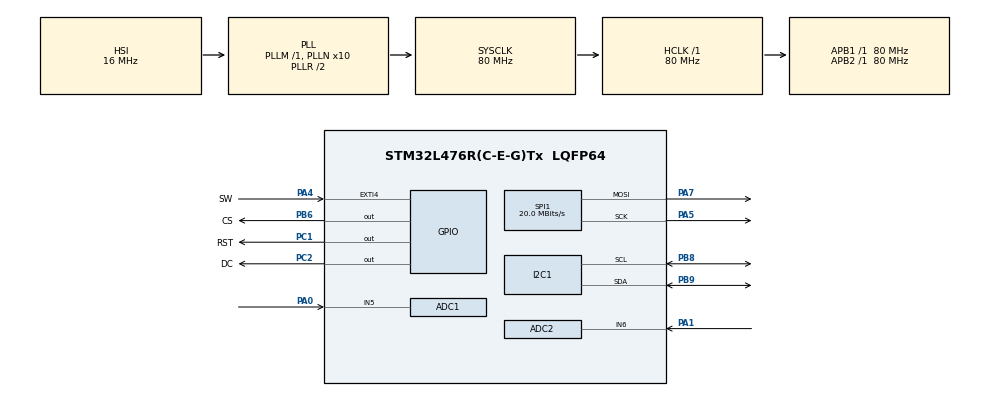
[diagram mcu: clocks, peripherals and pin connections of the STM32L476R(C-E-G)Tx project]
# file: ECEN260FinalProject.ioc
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ADC1.Channel-0\#ChannelRegularConversion=ADC_CHANNEL_5
ADC1.NbrOfConversionFlag=1
ADC1.OffsetNumber-0\#ChannelRegularConversion=ADC_OFFSET_NONE
ADC1.Rank-0\#ChannelRegularConversion=1
ADC1.SamplingTime-0\#ChannelRegularConversion=ADC_SAMPLETIME_2CYCLES_5
ADC1.master=1
ADC2.Channel-0\#ChannelRegularConversion=ADC_CHANNEL_6
ADC2.NbrOfConversionFlag=1
ADC2.OffsetNumber-0\#ChannelRegularConversion=ADC_OFFSET_NONE
ADC2.Rank-0\#ChannelRegularConversion=1
ADC2.SamplingTime-0\#ChannelRegularConversion=ADC_SAMPLETIME_2CYCLES_5
I2C1.Timing=0x10D19CE4
Mcu.Family=STM32L4
Mcu.Name=STM32L476R(C-E-G)Tx
Mcu.Package=LQFP64
NVIC.EXTI4_IRQn=true\:3\:0\:true\:false\:true\:true\:true\:true
NVIC.PriorityGroup=NVIC_PRIORITYGROUP_4
NVIC.TIM1_UP_TIM16_IRQn=true\:1\:0\:true\:false\:true\:true\:true\:true
PA0.Signal=ADCx_IN5
PA1.Signal=ADCx_IN6
PA13\ (JTMS-SWDIO).GPIO_Label=TMS
PA13\ (JTMS-SWDIO).Mode=Serial_Wire
PA13\ (JTMS-SWDIO).Signal=SYS_JTMS-SWDIO
PA14\ (JTCK-SWCLK).GPIO_Label=TCK
PA14\ (JTCK-SWCLK).Mode=Serial_Wire
PA14\ (JTCK-SWCLK).Signal=SYS_JTCK-SWCLK
PA4.GPIO_Label=SW
PA4.GPIO_PuPd=GPIO_PULLUP
PA4.Signal=GPXTI4
PA5.Mode=TX_Only_Simplex_Unidirect_Master
PA5.Signal=SPI1_SCK
PA7.Mode=TX_Only_Simplex_Unidirect_Master
PA7.Signal=SPI1_MOSI
PB3\ (JTDO-TRACESWO).GPIO_Label=SWO
PB3\ (JTDO-TRACESWO).Signal=SYS_JTDO-SWO
PB6.GPIO_Label=CS
PB6.Signal=GPIO_Output
PB8.GPIO_Pu=GPIO_PULLUP
PB8.Mode=I2C
PB8.Signal=I2C1_SCL
PB9.GPIO_Pu=GPIO_PULLUP
PB9.Mode=I2C
PB9.Signal=I2C1_SDA
PC1.GPIO_Label=RST
PC1.Signal=GPIO_Output
PC14-OSC32_IN\ (PC14).Mode=LSE-External-Oscillator
PC14-OSC32_IN\ (PC14).Signal=RCC_OSC32_IN
PC15-OSC32_OUT\ (PC15).Mode=LSE-External-Oscillator
PC15-OSC32_OUT\ (PC15).Signal=RCC_OSC32_OUT
PC2.GPIO_Label=DC
PC2.Signal=GPIO_Output
PH0-OSC_IN\ (PH0).Signal=RCC_OSC_IN
PH1-OSC_OUT\ (PH1).Signal=RCC_OSC_OUT
ProjectManager.HeapSize=0x200
ProjectManager.StackSize=0x400
ProjectManager.TargetToolchain=STM32CubeIDE
RCC.ADCFreq_Value=64000000
RCC.AHBFreq_Value=80000000
RCC.APB1Freq_Value=80000000
RCC.APB1TimFreq_Value=80000000
RCC.APB2Freq_Value=80000000
RCC.APB2TimFreq_Value=80000000
RCC.CortexFreq_Value=80000000
RCC.HCLKFreq_Value=80000000
RCC.HSE_VALUE=8000000
RCC.HSI_VALUE=16000000
RCC.MSI_VALUE=4000000
RCC.PLLN=10
RCC.PLLSourceVirtual=RCC_PLLSOURCE_HSI
RCC.PREFETCH_ENABLE=1
RCC.SYSCLKFreq_VALUE=80000000
RCC.SYSCLKSource=RCC_SYSCLKSOURCE_PLLCLK
RCC.USBFreq_Value=64000000
RCC.VCOOutputFreq_Value=160000000
SH.ADCx_IN5.0=ADC1_IN5,IN5-Single-Ended
SH.ADCx_IN6.0=ADC2_IN6,IN6-Single-Ended
SPI1.BaudRatePrescaler=SPI_BAUDRATEPRESCALER_4
SPI1.CalculateBaudRate=20.0 MBits/s
SPI1.DataSize=SPI_DATASIZE_8BIT
SPI1.Direction=SPI_DIRECTION_2LINES
SPI1.Mode=SPI_MODE_MASTER
SPI1.VirtualType=VM_MASTER
TIM16.Period=999
TIM16.Prescaler=7999
VP_TIM16_VS_ClockSourceINT.Mode=Enable_Timer
board=NUCLEO-L476RG

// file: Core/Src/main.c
/* USER CODE BEGIN Header */
/**
  ******************************************************************************
  * @file           : main.c
  * @brief          : Main program body
  ******************************************************************************
  * @attention
  *
  * Copyright (c) 2025 STMicroelectronics.
  * All rights reserved.
  *
  * This software is licensed under terms that can be found in the LICENSE file
  * in the root directory of this software component.
  * If no LICENSE file comes with this software, it is provided AS-IS.
  *
  ******************************************************************************
  *  Joystick:
  *GND - gnd
  *5V - 3.3V
  *VRx - PA0
  *VRy - PA1
  *SW - PA4
  *  I2C LCD
  *SCL - PB8
  *SDA - PB9
  *VCC - 5V
  *GND - gnd
  *  SPI LCD
  *GND - gnd
  *VDD - 3.3V
  *SCL - PA5
  *SDA - PA7
  *RST - PC1
  *DC - PC2
  *CS - PB6
  *BLK - 3.3V
  */
/* USER CODE END Header */
#include "main.h"

/* USER CODE BEGIN PM */
// 1602 I2C address
#define I2C_ADDR 0x27 // I2C address of the PCF8574
// 1602 dimensions
#define LCD_ROWS 2 // Number of rows on the LCD
#define LCD_COLS 16 // Number of columns on the LCD
// 1602 message bit numbers
#define DC_BIT 0 // Data/Command bit (register select bit)
#define EN_BIT 2 // Enable bit
#define BL_BIT 3 // Backlight bit
#define D4_BIT 4 // Data 4 bit
#define D5_BIT 5 // Data 5 bit
#define D6_BIT 6 // Data 6 bit
#define D7_BIT 7 // Data 7 bit
// Display dimensions
#define NUMROWS 160
#define NUMCOLS 128
// Common 16-bit RGB colors: bbbbb gggggg rrrrr
#define BLACK 0x0000 // 00000 000000 00000
#define WHITE 0xFFFF // 11111 111111 11111
#define BLUE 0xFD14  // 11111 101000 10100
// ST7735 command codes
#define SWRESET 0x01
#define SLPOUT 0x11
#define COLMOD 0x3A
#define MADCTL 0x36
#define DISPON 0x29
#define CASET 0x2A
#define RASET 0x2B
#define RAMWR 0x2C
#define COLOR_MODE_16BIT 0x05
#define MADCTL_DEFAULT 0xC8
/* USER CODE END PM */

ADC_HandleTypeDef hadc1;
ADC_HandleTypeDef hadc2;

I2C_HandleTypeDef hi2c1;

SPI_HandleTypeDef hspi1;

TIM_HandleTypeDef htim16;

/* USER CODE BEGIN PV */
// the background for the display
uint16_t background[160][128] = {
{0,0,0,0,0,0,0,0,0,0,0,0,0,0,0,0,0,0,0,0,0,0,0,0,0,0,0,0,0,0,0,0,0,0,0,0,0,0,0,0,0,0,1,0,0,0,0,0,0,0,0,0,0,0,0,0,0,0,0,0,0,0,0,0,0,0,0,0,0,0,0,0,0,0,0,0,0,0,0,0,0,0,0,0,1,0,0,0,0,0,0,0,0,0,0,0,0,0,0,0,0,0,0,0,0,0,0,0,0,0,0,0,0,0,0,0,0,0,0,0,0,0,0,0,0,0,0,0},
{0,0,0,0,0,0,0,0,0,0,0,0,0,0,0,0,0,0,0,0,0,0,0,0,0,0,0,0,0,0,0,0,0,0,0,0,0,0,0,0,0,0,1,0,0,0,0,0,0,0,0,0,0,0,0,0,0,0,0,0,0,0,0,0,0,0,0,0,0,0,0,0,0,0,0,0,0,0,0,0,0,0,0,0,1,0,0,0,0,0,0,0,0,0,0,0,0,0,0,0,0,0,0,0,0,0,0,0,0,0,0,0,0,0,0,0,0,0,0,0,0,0,0,0,0,0,0,0},
{0,0,0,0,0,0,0,0,0,0,0,0,0,0,0,0,0,0,0,0,0,0,0,0,0,0,0,0,0,0,0,0,0,0,0,0,0,0,0,0,0,0,1,0,0,0,0,0,0,0,0,0,0,0,0,0,0,0,0,0,0,0,0,0,0,0,0,0,0,0,0,0,0,0,0,0,0,0,0,0,0,0,0,0,1,0,0,0,0,0,0,0,0,0,0,0,0,0,0,0,0,0,0,0,0,0,0,0,0,0,0,0,0,0,0,0,0,0,0,0,0,0,0,0,0,0,0,0},
{0,0,0,0,0,0,0,0,0,0,0,0,0,0,0,0,0,0,0,0,0,0,0,0,0,0,0,0,0,0,0,0,0,0,0,0,0,0,0,0,0,0,1,0,0,0,0,0,0,0,0,0,0,0,0,0,0,0,0,0,0,0,0,0,0,0,0,0,0,0,0,0,0,0,0,0,0,0,0,0,0,0,0,0,1,0,0,0,0,0,0,0,0,0,0,0,0,0,0,0,0,0,0,0,0,0,0,0,0,0,0,0,0,0,0,0,0,0,0,0,0,0,0,0,0,0,0,0},
{0,0,0,0,0,0,0,0,0,0,0,0,0,0,0,0,0,0,0,0,0,0,0,0,0,0,0,0,0,0,0,0,0,0,0,0,0,0,0,0,0,0,1,0,0,0,0,0,0,0,0,0,0,0,0,0,0,0,0,0,0,0,0,0,0,0,0,0,0,0,0,0,0,0,0,0,0,0,0,0,0,0,0,0,1,0,0,0,0,0,0,0,0,0,0,0,0,0,0,0,0,0,0,0,0,0,0,0,0,0,0,0,0,0,0,0,0,0,0,0,0,0,0,0,0,0,0,0},
{0,0,0,0,0,0,0,0,0,0,0,0,0,0,0,0,0,0,0,0,0,0,0,0,0,0,0,0,0,0,0,0,0,0,0,0,0,0,0,0,0,0,1,0,0,0,0,0,0,0,0,0,0,0,0,0,0,0,0,0,0,0,0,0,0,0,0,0,0,0,0,0,0,0,0,0,0,0,0,0,0,0,0,0,1,0,0,0,0,0,0,0,0,0,0,0,0,0,0,0,0,0,0,0,0,0,0,0,0,0,0,0,0,0,0,0,0,0,0,0,0,0,0,0,0,0,0,0},
{0,0,0,0,0,0,0,0,0,0,0,0,0,0,0,0,0,0,0,0,0,0,0,0,0,0,0,0,0,0,0,0,0,0,0,0,0,0,0,0,0,0,1,0,0,0,0,0,0,0,0,0,0,0,0,0,0,0,0,0,0,0,0,0,0,0,0,0,0,0,0,0,0,0,0,0,0,0,0,0,0,0,0,0,1,0,0,0,0,0,0,0,0,0,0,0,0,0,0,0,0,0,0,0,0,0,0,0,0,0,0,0,0,0,0,0,0,0,0,0,0,0,0,0,0,0,0,0},
{0,0,0,0,0,0,0,0,0,0,0,0,0,0,0,0,0,0,0,0,0,0,0,0,0,0,0,0,0,0,0,0,0,0,0,0,0,0,0,0,0,0,1,0,0,0,0,0,0,0,0,0,0,0,0,0,0,0,0,0,0,0,0,0,0,0,0,0,0,0,0,0,0,0,0,0,0,0,0,0,0,0,0,0,1,0,0,0,0,0,0,0,0,0,0,0,0,0,0,0,0,0,0,0,0,0,0,0,0,0,0,0,0,0,0,0,0,0,0,0,0,0,0,0,0,0,0,0},
{0,0,0,0,0,0,0,0,0,0,0,0,0,0,0,0,0,0,0,0,0,0,0,0,0,0,0,0,0,0,0,0,0,0,0,0,0,0,0,0,0,0,1,0,0,0,0,0,0,0,0,0,0,0,0,0,0,0,0,0,0,0,0,0,0,0,0,0,0,0,0,0,0,0,0,0,0,0,0,0,0,0,0,0,1,0,0,0,0,0,0,0,0,0,0,0,0,0,0,0,0,0,0,0,0,0,0,0,0,0,0,0,0,0,0,0,0,0,0,0,0,0,0,0,0,0,0,0},
{0,0,0,0,0,0,0,0,0,0,0,0,0,0,0,0,0,0,0,0,0,0,0,0,0,0,0,0,0,0,0,0,0,0,0,0,0,0,0,0,0,0,1,0,0,0,0,0,0,0,0,0,0,0,0,0,0,0,0,0,0,0,0,0,0,0,0,0,0,0,0,0,0,0,0,0,0,0,0,0,0,0,0,0,1,0,0,0,0,0,0,0,0,0,0,0,0,0,0,0,0,0,0,0,0,0,0,0,0,0,0,0,0,0,0,0,0,0,0,0,0,0,0,0,0,0,0,0},
{0,0,0,0,0,0,0,0,0,0,1,1,1,1,1,1,1,1,1,1,1,1,1,1,1,1,1,1,1,1,1,1,0,0,0,0,0,0,0,0,0,0,1,0,0,0,0,0,0,0,0,0,0,0,0,0,0,0,0,0,0,1,1,1,1,1,0,0,0,0,0,0,0,0,0,0,0,0,0,0,0,0,0,0,1,0,0,0,0,0,0,0,0,0,0,0,0,0,0,0,0,1,1,1,1,1,1,1,1,0,0,0,0,0,0,0,0,0,0,0,0,0,0,0,0,0,0,0},
{0,0,0,0,0,0,0,0,0,0,0,0,0,0,0,0,0,0,0,0,0,0,0,0,0,0,0,0,0,0,0,1,0,0,0,0,0,0,0,0,0,0,1,0,0,0,0,0,0,0,0,0,0,0,0,0,0,0,1,1,1,0,0,0,0,0,1,1,1,0,0,0,0,0,0,0,0,0,0,0,0,0,0,0,1,0,0,0,0,0,0,0,0,0,0,0,0,0,0,1,1,0,0,0,0,0,0,0,0,1,1,0,0,0,0,0,0,0,0,0,0,0,0,0,0,0,0,0},
{0,0,0,0,0,0,0,0,0,0,0,0,0,0,0,0,0,0,0,0,0,0,0,0,0,0,0,0,0,0,0,1,0,0,0,0,0,0,0,0,0,0,1,0,0,0,0,0,0,0,0,0,0,0,0,0,1,1,0,0,0,0,0,0,0,0,0,0,0,1,1,0,0,0,0,0,0,0,0,0,0,0,0,0,1,0,0,0,0,0,0,0,0,0,0,0,0,1,1,0,0,0,0,0,0,0,0,0,0,0,0,1,1,0,0,0,0,0,0,0,0,0,0,0,0,0,0,0},
{0,0,0,0,0,0,0,0,0,0,0,0,0,0,0,0,0,0,0,0,0,0,0,0,0,0,0,0,0,0,1,0,0,0,0,0,0,0,0,0,0,0,1,0,0,0,0,0,0,0,0,0,0,0,0,1,0,0,0,0,0,0,0,0,0,0,0,0,0,0,0,1,0,0,0,0,0,0,0,0,0,0,0,0,1,0,0,0,0,0,0,0,0,0,0,0,1,0,0,0,0,0,0,0,0,0,0,0,0,0,0,0,0,1,0,0,0,0,0,0,0,0,0,0,0,0,0,0},
{0,0,0,0,0,0,0,0,0,0,0,0,0,0,0,0,0,0,0,0,0,0,0,0,0,0,0,0,0,0,1,0,0,0,0,0,0,0,0,0,0,0,1,0,0,0,0,0,0,0,0,0,0,0,1,1,0,0,0,0,0,0,0,0,0,0,0,0,0,0,0,0,1,0,0,0,0,0,0,0,0,0,0,0,1,0,0,0,0,0,0,0,0,0,0,0,1,0,0,0,0,0,0,0,0,0,0,0,0,0,0,0,0,1,0,0,0,0,0,0,0,0,0,0,0,0,0,0},
{0,0,0,0,0,0,0,0,0,0,0,0,0,0,0,0,0,0,0,0,0,0,0,0,0,0,0,0,0,1,0,0,0,0,0,0,0,0,0,0,0,0,1,0,0,0,0,0,0,0,0,0,0,1,0,0,0,0,0,0,0,0,0,0,0,0,0,0,0,0,0,0,0,1,0,0,0,0,0,0,0,0,0,0,1,0,0,0,0,0,0,0,0,0,0,1,0,0,0,0,0,0,0,0,0,0,0,0,0,0,0,0,0,0,1,0,0,0,0,0,0,0,0,0,0,0,0,0},
{0,0,0,0,0,0,0,0,0,0,0,0,0,0,0,0,0,0,0,0,0,0,0,0,0,0,0,0,0,1,0,0,0,0,0,0,0,0,0,0,0,0,1,0,0,0,0,0,0,0,0,0,0,1,0,0,0,0,0,0,0,0,0,0,0,0,0,0,0,0,0,0,0,1,0,0,0,0,0,0,0,0,0,0,1,0,0,0,0,0,0,0,0,0,0,1,0,0,0,0,0,0,0,0,0,0,0,0,0,0,0,0,0,0,1,0,0,0,0,0,0,0,0,0,0,0,0,0},
{0,0,0,0,0,0,0,0,0,0,0,0,0,0,0,0,0,0,0,0,0,0,0,0,0,0,0,0,1,0,0,0,0,0,0,0,0,0,0,0,0,0,1,0,0,0,0,0,0,0,0,0,0,1,0,0,0,0,0,0,0,0,0,0,0,0,0,0,0,0,0,0,0,1,0,0,0,0,0,0,0,0,0,0,1,0,0,0,0,0,0,0,0,0,1,0,0,0,0,0,0,0,0,0,0,0,0,0,0,0,0,0,0,0,0,1,0,0,0,0,0,0,0,0,0,0,0,0},
{0,0,0,0,0,0,0,0,0,0,0,0,0,0,0,0,0,0,0,0,0,0,0,0,0,0,0,0,1,0,0,0,0,0,0,0,0,0,0,0,0,0,1,0,0,0,0,0,0,0,0,0,0,1,0,0,0,0,0,0,0,0,0,0,0,0,0,0,0,0,0,0,0,1,0,0,0,0,0,0,0,0,0,0,1,0,0,0,0,0,0,0,0,0,1,0,0,0,0,0,0,0,0,0,0,0,0,0,0,0,0,0,0,0,0,1,0,0,0,0,0,0,0,0,0,0,0,0},
{0,0,0,0,0,0,0,0,0,0,0,0,0,0,0,0,0,0,0,0,0,0,0,0,0,0,0,1,0,0,0,0,0,0,0,0,0,0,0,0,0,0,1,0,0,0,0,0,0,0,0,0,0,1,0,0,0,0,0,0,0,0,0,0,0,0,0,0,0,0,0,0,0,1,0,0,0,0,0,0,0,0,0,0,1,0,0,0,0,0,0,0,0,0,1,0,0,0,0,0,0,0,0,0,0,0,0,0,0,0,0,0,0,0,0,1,0,0,0,0,0,0,0,0,0,0,0,0},
{0,0,0,0,0,0,0,0,0,0,0,0,0,0,0,0,0,0,0,0,0,0,0,0,0,0,0,1,0,0,0,0,0,0,0,0,0,0,0,0,0,0,1,0,0,0,0,0,0,0,0,0,0,0,1,0,0,0,0,0,0,0,0,0,0,0,0,0,0,0,0,0,1,0,0,0,0,0,0,0,0,0,0,0,1,0,0,0,0,0,0,0,0,0,1,0,0,0,0,0,0,0,0,0,0,0,0,0,0,0,0,0,0,0,0,1,0,0,0,0,0,0,0,0,0,0,0,0},
{0,0,0,0,0,0,0,0,0,0,0,0,0,0,0,0,0,0,0,0,0,0,0,0,0,0,1,0,0,0,0,0,0,0,0,0,0,0,0,0,0,0,1,0,0,0,0,0,0,0,0,0,0,0,0,1,0,0,0,0,0,0,0,0,0,0,0,0,0,0,0,1,0,0,0,0,0,0,0,0,0,0,0,0,1,0,0,0,0,0,0,0,0,0,1,0,0,0,0,0,0,0,0,0,0,0,0,0,0,0,0,0,0,0,0,1,0,0,0,0,0,0,0,0,0,0,0,0},
{0,0,0,0,0,0,0,0,0,0,0,0,0,0,0,0,0,0,0,0,0,0,0,0,0,0,1,0,0,0,0,0,0,0,0,0,0,0,0,0,0,0,1,0,0,0,0,0,0,0,0,0,0,0,0,0,1,1,1,0,0,0,0,0,0,0,0,0,1,1,1,0,0,0,0,0,0,0,0,0,0,0,0,0,1,0,0,0,0,0,0,0,0,0,1,0,0,0,0,0,0,0,0,0,0,0,0,0,0,0,0,0,0,0,0,1,0,0,0,0,0,0,0,0,0,0,0,0},
{0,0,0,0,0,0,0,0,0,0,0,0,0,0,0,0,0,0,0,0,0,0,0,0,0,1,0,0,0,0,0,0,0,0,0,0,0,0,0,0,0,0,1,0,0,0,0,0,0,0,0,0,0,0,0,0,0,0,0,1,1,1,0,0,0,1,1,1,0,0,0,0,0,0,0,0,0,0,0,0,0,0,0,0,1,0,0,0,0,0,0,0,0,0,0,1,0,0,0,0,0,0,0,0,0,0,0,0,0,0,0,0,0,0,1,1,0,0,0,0,0,0,0,0,0,0,0,0},
{0,0,0,0,0,0,0,0,0,0,0,0,0,0,0,0,0,0,0,0,0,0,0,0,0,1,0,0,0,0,0,0,0,0,0,0,0,0,0,0,0,0,1,0,0,0,0,0,0,0,0,0,0,0,0,0,0,0,0,0,0,0,1,1,1,0,0,0,0,0,0,0,0,0,0,0,0,0,0,0,0,0,0,0,1,0,0,0,0,0,0,0,0,0,0,1,0,0,0,0,0,0,0,0,0,0,0,0,0,0,0,0,0,0,1,1,0,0,0,0,0,0,0,0,0,0,0,0},
{0,0,0,0,0,0,0,0,0,0,0,0,0,0,0,0,0,0,0,0,0,0,0,0,1,0,0,0,0,0,0,0,0,0,0,0,0,0,0,0,0,0,1,0,0,0,0,0,0,0,0,0,0,0,0,0,0,0,0,1,1,1,0,0,0,1,1,1,0,0,0,0,0,0,0,0,0,0,0,0,0,0,0,0,1,0,0,0,0,0,0,0,0,0,0,0,1,0,0,0,0,0,0,0,0,0,0,0,0,0,0,0,0,1,0,1,0,0,0,0,0,0,0,0,0,0,0,0},
{0,0,0,0,0,0,0,0,0,0,0,0,0,0,0,0,0,0,0,0,0,0,0,0,1,0,0,0,0,0,0,0,0,0,0,0,0,0,0,0,0,0,1,0,0,0,0,0,0,0,0,0,0,0,0,0,0,1,1,0,0,0,0,0,0,0,0,0,1,1,0,0,0,0,0,0,0,0,0,0,0,0,0,0,1,0,0,0,0,0,0,0,0,0,0,0,1,0,0,0,0,0,0,0,0,0,0,0,0,0,0,0,0,1,0,1,0,0,0,0,0,0,0,0,0,0,0,0},
{0,0,0,0,0,0,0,0,0,0,0,0,0,0,0,0,0,0,0,0,0,0,0,1,0,0,0,0,0,0,0,0,0,0,0,0,0,0,0,0,0,0,1,0,0,0,0,0,0,0,0,0,0,0,0,0,1,0,0,0,0,0,0,0,0,0,0,0,0,0,1,0,0,0,0,0,0,0,0,0,0,0,0,0,1,0,0,0,0,0,0,0,0,0,0,0,0,1,1,0,0,0,0,0,0,0,0,0,0,0,0,1,1,0,0,1,0,0,0,0,0,0,0,0,0,0,0,0},
{0,0,0,0,0,0,0,0,0,0,0,0,0,0,0,0,0,0,0,0,0,0,0,1,0,0,0,0,0,0,0,0,0,0,0,0,0,0,0,0,0,0,1,0,0,0,0,0,0,0,0,0,0,0,0,1,0,0,0,0,0,0,0,0,0,0,0,0,0,0,0,1,0,0,0,0,0,0,0,0,0,0,0,0,1,0,0,0,0,0,0,0,0,0,0,0,0,0,0,1,1,0,0,0,0,0,0,0,0,1,1,0,0,0,0,1,0,0,0,0,0,0,0,0,0,0,0,0},
{0,0,0,0,0,0,0,0,0,0,0,0,0,0,0,0,0,0,0,0,0,0,1,0,0,0,0,0,0,0,0,0,0,0,0,0,0,0,0,0,0,0,1,0,0,0,0,0,0,0,0,0,0,0,1,0,0,0,0,0,0,0,0,0,0,0,0,0,0,0,0,0,1,0,0,0,0,0,0,0,0,0,0,0,1,0,0,0,0,0,0,0,0,0,0,0,0,0,0,0,0,1,1,1,1,1,1,1,1,0,0,0,0,0,1,0,0,0,0,0,0,0,0,0,0,0,0,0},
{0,0,0,0,0,0,0,0,0,0,0,0,0,0,0,0,0,0,0,0,0,0,1,0,0,0,0,0,0,0,0,0,0,0,0,0,0,0,0,0,0,0,1,0,0,0,0,0,0,0,0,0,0,1,0,0,0,0,0,0,0,0,0,0,0,0,0,0,0,0,0,0,0,1,0,0,0,0,0,0,0,0,0,0,1,0,0,0,0,0,0,0,0,0,0,0,0,0,0,0,0,0,0,0,0,0,0,0,0,0,0,0,0,0,1,0,0,0,0,0,0,0,0,0,0,0,0,0},
{0,0,0,0,0,0,0,0,0,0,0,0,0,0,0,0,0,0,0,0,0,1,0,0,0,0,0,0,0,0,0,0,0,0,0,0,0,0,0,0,0,0,1,0,0,0,0,0,0,0,0,0,0,1,0,0,0,0,0,0,0,0,0,0,0,0,0,0,0,0,0,0,0,1,0,0,0,0,0,0,0,0,0,0,1,0,0,0,0,0,0,0,0,0,0,0,0,0,0,0,0,0,0,0,0,0,0,0,0,0,0,0,0,0,1,0,0,0,0,0,0,0,0,0,0,0,0,0},
{0,0,0,0,0,0,0,0,0,0,0,0,0,0,0,0,0,0,0,0,0,1,0,0,0,0,0,0,0,0,0,0,0,0,0,0,0,0,0,0,0,0,1,0,0,0,0,0,0,0,0,0,0,1,0,0,0,0,0,0,0,0,0,0,0,0,0,0,0,0,0,0,0,1,0,0,0,0,0,0,0,0,0,0,1,0,0,0,0,0,0,0,0,0,0,0,0,0,0,0,0,0,0,0,0,0,0,0,0,0,0,0,0,1,0,0,0,0,0,0,0,0,0,0,0,0,0,0},
{0,0,0,0,0,0,0,0,0,0,0,0,0,0,0,0,0,0,0,0,1,0,0,0,0,0,0,0,0,0,0,0,0,0,0,0,0,0,0,0,0,0,1,0,0,0,0,0,0,0,0,0,0,1,0,0,0,0,0,0,0,0,0,0,0,0,0,0,0,0,0,0,0,1,0,0,0,0,0,0,0,0,0,0,1,0,0,0,0,0,0,0,0,0,0,0,0,0,0,0,0,0,0,0,0,0,0,0,0,0,0,0,0,1,0,0,0,0,0,0,0,0,0,0,0,0,0,0},
{0,0,0,0,0,0,0,0,0,0,0,0,0,0,0,0,0,0,0,0,1,0,0,0,0,0,0,0,0,0,0,0,0,0,0,0,0,0,0,0,0,0,1,0,0,0,0,0,0,0,0,0,0,1,0,0,0,0,0,0,0,0,0,0,0,0,0,0,0,0,0,0,0,1,0,0,0,0,0,0,0,0,0,0,1,0,0,0,0,0,0,0,0,0,0,0,0,0,0,0,0,0,0,0,0,0,0,0,0,0,0,0,0,1,0,0,0,0,0,0,0,0,0,0,0,0,0,0},
{0,0,0,0,0,0,0,0,0,0,0,0,0,0,0,0,0,0,0,1,0,0,0,0,0,0,0,0,0,0,0,0,0,0,0,0,0,0,0,0,0,0,1,0,0,0,0,0,0,0,0,0,0,0,1,0,0,0,0,0,0,0,0,0,0,0,0,0,0,0,0,0,1,0,0,0,0,0,0,0,0,0,0,0,1,0,0,0,0,0,0,0,0,0,0,0,0,0,0,0,0,0,0,0,0,0,0,0,0,0,0,0,1,0,0,0,0,0,0,0,0,0,0,0,0,0,0,0},
{0,0,0,0,0,0,0,0,0,0,0,0,0,0,0,0,0,0,0,1,0,0,0,0,0,0,0,0,0,0,0,0,0,0,0,0,0,0,0,0,0,0,1,0,0,0,0,0,0,0,0,0,0,0,1,0,0,0,0,0,0,0,0,0,0,0,0,0,0,0,0,0,1,0,0,0,0,0,0,0,0,0,0,0,1,0,0,0,0,0,0,0,0,0,0,0,0,0,0,0,0,0,0,0,0,0,0,0,0,0,0,0,1,0,0,0,0,0,0,0,0,0,0,0,0,0,0,0},
{0,0,0,0,0,0,0,0,0,0,0,0,0,0,0,0,0,0,1,0,0,0,0,0,0,0,0,0,0,0,0,0,0,0,0,0,0,0,0,0,0,0,1,0,0,0,0,0,0,0,0,0,0,0,0,1,0,0,0,0,0,0,0,0,0,0,0,0,0,0,0,1,0,0,0,0,0,0,0,0,0,0,0,0,1,0,0,0,0,0,0,0,0,0,0,0,0,0,0,0,0,0,0,0,0,0,0,0,0,0,0,1,0,0,0,0,0,0,0,0,0,0,0,0,0,0,0,0},
{0,0,0,0,0,0,0,0,0,0,0,0,0,0,0,0,0,0,1,0,0,0,0,0,0,0,0,0,0,0,0,0,0,0,0,0,0,0,0,0,0,0,1,0,0,0,0,0,0,0,0,0,0,0,0,1,0,0,0,0,0,0,0,0,0,0,0,0,0,0,0,1,0,0,0,0,0,0,0,0,0,0,0,0,1,0,0,0,0,0,0,0,0,0,0,0,0,0,0,0,0,0,0,0,0,0,0,0,0,0,0,1,0,0,0,0,0,0,0,0,0,0,0,0,0,0,0,0},
{0,0,0,0,0,0,0,0,0,0,0,0,0,0,0,0,0,1,0,0,0,0,0,0,0,0,0,0,0,0,0,0,0,0,0,0,0,0,0,0,0,0,1,0,0,0,0,0,0,0,0,0,0,0,0,0,1,1,0,0,0,0,0,0,0,0,0,0,0,1,1,0,0,0,0,0,0,0,0,0,0,0,0,0,1,0,0,0,0,0,0,0,0,0,0,0,0,0,0,0,0,0,0,0,0,0,0,0,0,0,1,0,0,0,0,0,0,0,0,0,0,0,0,0,0,0,0,0},
{0,0,0,0,0,0,0,0,0,0,0,0,0,0,0,0,0,1,0,0,0,0,0,0,0,0,0,0,0,0,0,0,0,0,0,0,0,0,0,0,0,0,1,0,0,0,0,0,0,0,0,0,0,0,0,0,0,0,1,1,0,0,0,0,0,0,0,1,1,0,0,0,0,0,0,0,0,0,0,0,0,0,0,0,1,0,0,0,0,0,0,0,0,0,0,0,0,0,0,0,0,0,0,0,0,0,0,0,1,1,0,0,0,0,0,0,0,0,0,0,0,0,0,0,0,0,0,0},
{0,0,0,0,0,0,0,0,0,0,0,0,0,0,0,0,1,0,0,0,0,0,0,0,0,0,0,0,0,0,0,0,0,0,0,0,0,0,0,0,0,0,1,0,0,0,0,0,0,0,0,0,0,0,0,0,0,0,0,0,1,1,1,1,1,1,1,0,0,0,0,0,0,0,0,0,0,0,0,0,0,0,0,0,1,0,0,0,0,0,0,0,0,0,0,0,0,0,0,0,0,1,1,1,1,1,1,1,0,0,0,0,0,0,0,0,0,0,0,0,0,0,0,0,0,0,0,0},
{0,0,0,0,0,0,0,0,0,0,0,0,0,0,0,0,0,0,0,0,0,0,0,0,0,0,0,0,0,0,0,0,0,0,0,0,0,0,0,0,0,0,1,0,0,0,0,0,0,0,0,0,0,0,0,0,0,0,0,0,0,0,0,0,0,0,0,0,0,0,0,0,0,0,0,0,0,0,0,0,0,0,0,0,1,0,0,0,0,0,0,0,0,0,0,0,0,0,0,0,0,0,0,0,0,0,0,0,0,0,0,0,0,0,0,0,0,0,0,0,0,0,0,0,0,0,0,0},
{0,0,0,0,0,0,0,0,0,0,0,0,0,0,0,0,0,0,0,0,0,0,0,0,0,0,0,0,0,0,0,0,0,0,0,0,0,0,0,0,0,0,1,0,0,0,0,0,0,0,0,0,0,0,0,0,0,0,0,0,0,0,0,0,0,0,0,0,0,0,0,0,0,0,0,0,0,0,0,0,0,0,0,0,1,0,0,0,0,0,0,0,0,0,0,0,0,0,0,0,0,0,0,0,0,0,0,0,0,0,0,0,0,0,0,0,0,0,0,0,0,0,0,0,0,0,0,0},
{0,0,0,0,0,0,0,0,0,0,0,0,0,0,0,0,0,0,0,0,0,0,0,0,0,0,0,0,0,0,0,0,0,0,0,0,0,0,0,0,0,0,1,0,0,0,0,0,0,0,0,0,0,0,0,0,0,0,0,0,0,0,0,0,0,0,0,0,0,0,0,0,0,0,0,0,0,0,0,0,0,0,0,0,1,0,0,0,0,0,0,0,0,0,0,0,0,0,0,0,0,0,0,0,0,0,0,0,0,0,0,0,0,0,0,0,0,0,0,0,0,0,0,0,0,0,0,0},
{0,0,0,0,0,0,0,0,0,0,0,0,0,0,0,0,0,0,0,0,0,0,0,0,0,0,0,0,0,0,0,0,0,0,0,0,0,0,0,0,0,0,1,0,0,0,0,0,0,0,0,0,0,0,0,0,0,0,0,0,0,0,0,0,0,0,0,0,0,0,0,0,0,0,0,0,0,0,0,0,0,0,0,0,1,0,0,0,0,0,0,0,0,0,0,0,0,0,0,0,0,0,0,0,0,0,0,0,0,0,0,0,0,0,0,0,0,0,0,0,0,0,0,0,0,0,0,0},
{0,0,0,0,0,0,0,0,0,0,0,0,0,0,0,0,0,0,0,0,0,0,0,0,0,0,0,0,0,0,0,0,0,0,0,0,0,0,0,0,0,0,1,0,0,0,0,0,0,0,0,0,0,0,0,0,0,0,0,0,0,0,0,0,0,0,0,0,0,0,0,0,0,0,0,0,0,0,0,0,0,0,0,0,1,0,0,0,0,0,0,0,0,0,0,0,0,0,0,0,0,0,0,0,0,0,0,0,0,0,0,0,0,0,0,0,0,0,0,0,0,0,0,0,0,0,0,0},
{0,0,0,0,0,0,0,0,0,0,0,0,0,0,0,0,0,0,0,0,0,0,0,0,0,0,0,0,0,0,0,0,0,0,0,0,0,0,0,0,0,0,1,0,0,0,0,0,0,0,0,0,0,0,0,0,0,0,0,0,0,0,0,0,0,0,0,0,0,0,0,0,0,0,0,0,0,0,0,0,0,0,0,0,1,0,0,0,0,0,0,0,0,0,0,0,0,0,0,0,0,0,0,0,0,0,0,0,0,0,0,0,0,0,0,0,0,0,0,0,0,0,0,0,0,0,0,0},
{0,0,0,0,0,0,0,0,0,0,0,0,0,0,0,0,0,0,0,0,0,0,0,0,0,0,0,0,0,0,0,0,0,0,0,0,0,0,0,0,0,0,1,0,0,0,0,0,0,0,0,0,0,0,0,0,0,0,0,0,0,0,0,0,0,0,0,0,0,0,0,0,0,0,0,0,0,0,0,0,0,0,0,0,1,0,0,0,0,0,0,0,0,0,0,0,0,0,0,0,0,0,0,0,0,0,0,0,0,0,0,0,0,0,0,0,0,0,0,0,0,0,0,0,0,0,0,0},
{0,0,0,0,0,0,0,0,0,0,0,0,0,0,0,0,0,0,0,0,0,0,0,0,0,0,0,0,0,0,0,0,0,0,0,0,0,0,0,0,0,0,1,0,0,0,0,0,0,0,0,0,0,0,0,0,0,0,0,0,0,0,0,0,0,0,0,0,0,0,0,0,0,0,0,0,0,0,0,0,0,0,0,0,1,0,0,0,0,0,0,0,0,0,0,0,0,0,0,0,0,0,0,0,0,0,0,0,0,0,0,0,0,0,0,0,0,0,0,0,0,0,0,0,0,0,0,0},
{0,0,0,0,0,0,0,0,0,0,0,0,0,0,0,0,0,0,0,0,0,0,0,0,0,0,0,0,0,0,0,0,0,0,0,0,0,0,0,0,0,0,1,0,0,0,0,0,0,0,0,0,0,0,0,0,0,0,0,0,0,0,0,0,0,0,0,0,0,0,0,0,0,0,0,0,0,0,0,0,0,0,0,0,1,0,0,0,0,0,0,0,0,0,0,0,0,0,0,0,0,0,0,0,0,0,0,0,0,0,0,0,0,0,0,0,0,0,0,0,0,0,0,0,0,0,0,0},
{0,0,0,0,0,0,0,0,0,0,0,0,0,0,0,0,0,0,0,0,0,0,0,0,0,0,0,0,0,0,0,0,0,0,0,0,0,0,0,0,0,0,1,0,0,0,0,0,0,0,0,0,0,0,0,0,0,0,0,0,0,0,0,0,0,0,0,0,0,0,0,0,0,0,0,0,0,0,0,0,0,0,0,0,1,0,0,0,0,0,0,0,0,0,0,0,0,0,0,0,0,0,0,0,0,0,0,0,0,0,0,0,0,0,0,0,0,0,0,0,0,0,0,0,0,0,0,0},
{1,1,1,1,1,1,1,1,1,1,1,1,1,1,1,1,1,1,1,1,1,1,1,1,1,1,1,1,1,1,1,1,1,1,1,1,1,1,1,1,1,1,1,1,1,1,1,1,1,1,1,1,1,1,1,1,1,1,1,1,1,1,1,1,1,1,1,1,1,1,1,1,1,1,1,1,1,1,1,1,1,1,1,1,1,1,1,1,1,1,1,1,1,1,1,1,1,1,1,1,1,1,1,1,1,1,1,1,1,1,1,1,1,1,1,1,1,1,1,1,1,1,1,1,1,1,1,1},
{0,0,0,0,0,0,0,0,0,0,0,0,0,0,0,0,0,0,0,0,0,0,0,0,0,0,0,0,0,0,0,0,0,0,0,0,0,0,0,0,0,0,1,0,0,0,0,0,0,0,0,0,0,0,0,0,0,0,0,0,0,0,0,0,0,0,0,0,0,0,0,0,0,0,0,0,0,0,0,0,0,0,0,0,1,0,0,0,0,0,0,0,0,0,0,0,0,0,0,0,0,0,0,0,0,0,0,0,0,0,0,0,0,0,0,0,0,0,0,0,0,0,0,0,0,0,0,0},
{0,0,0,0,0,0,0,0,0,0,0,0,0,0,0,0,0,0,0,0,0,0,0,0,0,0,0,0,0,0,0,0,0,0,0,0,0,0,0,0,0,0,1,0,0,0,0,0,0,0,0,0,0,0,0,0,0,0,0,0,0,0,0,0,0,0,0,0,0,0,0,0,0,0,0,0,0,0,0,0,0,0,0,0,1,0,0,0,0,0,0,0,0,0,0,0,0,0,0,0,0,0,0,0,0,0,0,0,0,0,0,0,0,0,0,0,0,0,0,0,0,0,0,0,0,0,0,0},
{0,0,0,0,0,0,0,0,0,0,0,0,0,0,0,0,0,0,0,0,0,0,0,0,0,0,0,0,0,0,0,0,0,0,0,0,0,0,0,0,0,0,1,0,0,0,0,0,0,0,0,0,0,0,0,0,0,0,0,0,0,0,0,0,0,0,0,0,0,0,0,0,0,0,0,0,0,0,0,0,0,0,0,0,1,0,0,0,0,0,0,0,0,0,0,0,0,0,0,0,0,0,0,0,0,0,0,0,0,0,0,0,0,0,0,0,0,0,0,0,0,0,0,0,0,0,0,0},
{0,0,0,0,0,0,0,0,0,0,0,0,0,0,0,0,0,0,0,0,0,0,0,0,0,0,0,0,0,0,0,0,0,0,0,0,0,0,0,0,0,0,1,0,0,0,0,0,0,0,0,0,0,0,0,0,0,0,0,0,0,0,0,0,0,0,0,0,0,0,0,0,0,0,0,0,0,0,0,0,0,0,0,0,1,0,0,0,0,0,0,0,0,0,0,0,0,0,0,0,0,0,0,0,0,0,0,0,0,0,0,0,0,0,0,0,0,0,0,0,0,0,0,0,0,0,0,0},
{0,0,0,0,0,0,0,0,0,0,0,0,0,0,0,0,0,0,0,0,0,0,0,0,0,0,0,0,0,0,0,0,0,0,0,0,0,0,0,0,0,0,1,0,0,0,0,0,0,0,0,0,0,0,0,0,0,0,0,0,0,0,0,0,0,0,0,0,0,0,0,0,0,0,0,0,0,0,0,0,0,0,0,0,1,0,0,0,0,0,0,0,0,0,0,0,0,0,0,0,0,0,0,0,0,0,0,0,0,0,0,0,0,0,0,0,0,0,0,0,0,0,0,0,0,0,0,0},
{0,0,0,0,0,0,0,0,0,0,0,0,0,0,0,0,0,0,0,0,0,0,0,0,0,0,0,0,0,0,0,0,0,0,0,0,0,0,0,0,0,0,1,0,0,0,0,0,0,0,0,0,0,0,0,0,0,0,0,0,0,0,0,0,0,0,0,0,0,0,0,0,0,0,0,0,0,0,0,0,0,0,0,0,1,0,0,0,0,0,0,0,0,0,0,0,0,0,0,0,0,0,0,0,0,0,0,0,0,0,0,0,0,0,0,0,0,0,0,0,0,0,0,0,0,0,0,0},
{0,0,0,0,0,0,0,0,0,0,0,0,0,0,0,0,0,0,0,0,0,0,0,0,0,0,0,0,0,0,0,0,0,0,0,0,0,0,0,0,0,0,1,0,0,0,0,0,0,0,0,0,0,0,0,0,0,0,0,0,0,0,0,0,0,0,0,0,0,0,0,0,0,0,0,0,0,0,0,0,0,0,0,0,1,0,0,0,0,0,0,0,0,0,0,0,0,0,0,0,0,0,0,0,0,0,0,0,0,0,0,0,0,0,0,0,0,0,0,0,0,0,0,0,0,0,0,0},
{0,0,0,0,0,0,0,0,0,0,0,0,0,0,0,0,0,0,0,0,0,0,0,0,0,0,0,0,0,0,0,0,0,0,0,0,0,0,0,0,0,0,1,0,0,0,0,0,0,0,0,0,0,0,0,0,0,0,0,0,0,0,0,0,0,0,0,0,0,0,0,0,0,0,0,0,0,0,0,0,0,0,0,0,1,0,0,0,0,0,0,0,0,0,0,0,0,0,0,0,0,0,0,0,0,0,0,0,0,0,0,0,0,0,0,0,0,0,0,0,0,0,0,0,0,0,0,0},
{0,0,0,0,0,0,0,0,0,0,0,0,0,0,0,0,0,0,0,0,0,0,0,1,0,0,0,0,0,0,0,0,0,0,0,0,0,0,0,0,0,0,1,0,0,0,0,0,0,0,0,0,0,0,0,0,0,0,0,0,0,0,0,0,0,0,0,0,0,0,0,0,0,0,0,0,0,0,0,0,0,0,0,0,1,0,0,0,0,0,0,0,0,0,0,0,0,0,0,0,0,0,0,0,0,0,0,0,0,0,0,0,0,0,0,0,0,0,0,0,0,0,0,0,0,0,0,0},
{0,0,0,0,0,0,0,0,0,0,0,0,0,0,0,0,0,0,0,0,0,0,1,1,0,0,0,0,0,0,0,0,0,0,0,0,0,0,0,0,0,0,1,0,0,0,0,0,0,0,0,0,0,0,0,0,0,0,0,0,0,0,0,0,0,0,0,0,0,0,0,0,0,0,0,0,0,0,0,0,0,0,0,0,1,0,0,0,0,0,0,0,0,0,0,0,0,0,0,0,0,0,0,0,0,0,0,0,0,0,0,0,0,0,0,0,0,0,0,0,0,0,0,0,0,0,0,0},
{0,0,0,0,0,0,0,0,0,0,0,0,0,0,0,0,0,0,0,0,0,1,0,1,0,0,0,0,0,0,0,0,0,0,0,0,0,0,0,0,0,0,1,0,0,0,0,0,0,0,0,0,0,1,1,1,1,1,1,1,1,1,1,1,1,1,1,1,1,1,1,1,1,1,0,0,0,0,0,0,0,0,0,0,1,0,0,0,0,0,0,0,0,0,0,0,0,0,0,0,0,0,0,0,0,0,1,1,1,1,0,0,0,0,0,0,0,0,0,0,0,0,0,0,0,0,0,0},
{0,0,0,0,0,0,0,0,0,0,0,0,0,0,0,0,0,0,0,0,1,0,0,1,0,0,0,0,0,0,0,0,0,0,0,0,0,0,0,0,0,0,1,0,0,0,0,0,0,0,0,0,0,1,0,0,0,0,0,0,0,0,0,0,0,0,0,0,0,0,0,0,0,0,0,0,0,0,0,0,0,0,0,0,1,0,0,0,0,0,0,0,0,0,0,0,0,0,0,0,0,0,0,1,1,1,0,0,0,0,0,0,0,0,0,0,0,0,0,0,0,0,0,0,0,0,0,0},
{0,0,0,0,0,0,0,0,0,0,0,0,0,0,0,0,0,0,0,1,0,0,0,1,0,0,0,0,0,0,0,0,0,0,0,0,0,0,0,0,0,0,1,0,0,0,0,0,0,0,0,0,0,1,0,0,0,0,0,0,0,0,0,0,0,0,0,0,0,0,0,0,0,0,0,0,0,0,0,0,0,0,0,0,1,0,0,0,0,0,0,0,0,0,0,0,0,0,0,0,0,1,1,0,0,0,0,0,0,0,0,0,0,0,0,0,0,0,0,0,0,0,0,0,0,0,0,0},
{0,0,0,0,0,0,0,0,0,0,0,0,0,0,0,0,0,0,1,0,0,0,0,1,0,0,0,0,0,0,0,0,0,0,0,0,0,0,0,0,0,0,1,0,0,0,0,0,0,0,0,0,0,1,0,0,0,0,0,0,0,0,0,0,0,0,0,0,0,0,0,0,0,0,0,0,0,0,0,0,0,0,0,0,1,0,0,0,0,0,0,0,0,0,0,0,0,0,0,0,1,0,0,0,0,0,0,0,0,0,0,0,0,0,0,0,0,0,0,0,0,0,0,0,0,0,0,0},
{0,0,0,0,0,0,0,0,0,0,0,0,0,0,0,0,0,1,0,0,0,0,0,1,0,0,0,0,0,0,0,0,0,0,0,0,0,0,0,0,0,0,1,0,0,0,0,0,0,0,0,0,0,1,0,0,0,0,0,0,0,0,0,0,0,0,0,0,0,0,0,0,0,0,0,0,0,0,0,0,0,0,0,0,1,0,0,0,0,0,0,0,0,0,0,0,0,0,0,1,0,0,0,0,0,0,0,0,0,0,0,0,0,0,0,0,0,0,0,0,0,0,0,0,0,0,0,0},
{0,0,0,0,0,0,0,0,0,0,0,0,0,0,0,0,1,0,0,0,0,0,0,1,0,0,0,0,0,0,0,0,0,0,0,0,0,0,0,0,0,0,1,0,0,0,0,0,0,0,0,0,0,1,0,0,0,0,0,0,0,0,0,0,0,0,0,0,0,0,0,0,0,0,0,0,0,0,0,0,0,0,0,0,1,0,0,0,0,0,0,0,0,0,0,0,0,0,1,0,0,0,0,0,0,0,0,0,0,0,0,0,0,0,0,0,0,0,0,0,0,0,0,0,0,0,0,0},
{0,0,0,0,0,0,0,0,0,0,0,0,0,0,0,1,0,0,0,0,0,0,0,1,0,0,0,0,0,0,0,0,0,0,0,0,0,0,0,0,0,0,1,0,0,0,0,0,0,0,0,0,0,1,0,0,0,0,0,0,0,0,0,0,0,0,0,0,0,0,0,0,0,0,0,0,0,0,0,0,0,0,0,0,1,0,0,0,0,0,0,0,0,0,0,0,0,0,1,0,0,0,0,0,0,0,0,0,0,0,0,0,0,0,0,0,0,0,0,0,0,0,0,0,0,0,0,0},
{0,0,0,0,0,0,0,0,0,0,0,0,0,0,1,0,0,0,0,0,0,0,0,1,0,0,0,0,0,0,0,0,0,0,0,0,0,0,0,0,0,0,1,0,0,0,0,0,0,0,0,0,0,1,0,0,0,0,0,0,0,0,0,0,0,0,0,0,0,0,0,0,0,0,0,0,0,0,0,0,0,0,0,0,1,0,0,0,0,0,0,0,0,0,0,0,0,1,0,0,0,0,0,0,0,0,0,0,0,0,0,0,0,0,0,0,0,0,0,0,0,0,0,0,0,0,0,0},
{0,0,0,0,0,0,0,0,0,0,0,0,0,1,0,0,0,0,0,0,0,0,0,1,0,0,0,0,0,0,0,0,0,0,0,0,0,0,0,0,0,0,1,0,0,0,0,0,0,0,0,0,0,1,0,0,0,0,0,0,0,0,0,0,0,0,0,0,0,0,0,0,0,0,0,0,0,0,0,0,0,0,0,0,1,0,0,0,0,0,0,0,0,0,0,0,0,1,0,0,0,0,0,0,0,0,0,0,0,0,0,0,0,0,0,0,0,0,0,0,0,0,0,0,0,0,0,0},
{0,0,0,0,0,0,0,0,0,0,0,0,1,0,0,0,0,0,0,0,0,0,0,1,0,0,0,0,0,0,0,0,0,0,0,0,0,0,0,0,0,0,1,0,0,0,0,0,0,0,0,0,0,1,0,0,0,0,0,0,0,0,0,0,0,0,0,0,0,0,0,0,0,0,0,0,0,0,0,0,0,0,0,0,1,0,0,0,0,0,0,0,0,0,0,0,0,1,0,0,0,0,0,0,0,0,0,0,0,0,0,0,0,0,0,0,0,0,0,0,0,0,0,0,0,0,0,0},
{0,0,0,0,0,0,0,0,0,0,0,1,0,0,0,0,0,0,0,0,0,0,0,1,0,0,0,0,0,0,0,0,0,0,0,0,0,0,0,0,0,0,1,0,0,0,0,0,0,0,0,0,0,1,0,0,0,0,0,0,0,0,0,0,0,0,0,0,0,0,0,0,0,0,0,0,0,0,0,0,0,0,0,0,1,0,0,0,0,0,0,0,0,0,0,0,1,0,0,0,0,0,0,0,0,0,0,0,0,0,0,0,0,0,0,0,0,0,0,0,0,0,0,0,0,0,0,0},
{0,0,0,0,0,0,0,0,0,0,1,0,0,0,0,0,0,0,0,0,0,0,0,1,0,0,0,0,0,0,0,0,0,0,0,0,0,0,0,0,0,0,1,0,0,0,0,0,0,0,0,0,0,1,0,0,0,0,0,0,0,0,0,0,0,0,0,0,0,0,0,0,0,0,0,0,0,0,0,0,0,0,0,0,1,0,0,0,0,0,0,0,0,0,0,0,1,0,0,0,0,0,0,0,0,0,0,0,0,0,0,0,0,0,0,0,0,0,0,0,0,0,0,0,0,0,0,0},
{0,0,0,0,0,0,0,0,0,1,0,0,0,0,0,0,0,0,0,0,0,0,0,1,0,0,0,0,0,0,0,0,0,0,0,0,0,0,0,0,0,0,1,0,0,0,0,0,0,0,0,0,0,1,0,0,0,0,0,0,0,0,0,0,0,0,0,0,0,0,0,0,0,0,0,0,0,0,0,0,0,0,0,0,1,0,0,0,0,0,0,0,0,0,0,0,1,0,0,0,0,0,0,0,0,0,0,0,0,0,0,0,0,0,0,0,0,0,0,0,0,0,0,0,0,0,0,0},
{0,0,0,0,0,0,0,0,1,1,1,1,1,1,1,1,1,1,1,1,1,1,1,1,1,1,1,1,1,1,1,0,0,0,0,0,0,0,0,0,0,0,1,0,0,0,0,0,0,0,0,0,0,1,0,0,0,0,0,0,1,1,1,1,1,1,1,0,0,0,0,0,0,0,0,0,0,0,0,0,0,0,0,0,1,0,0,0,0,0,0,0,0,0,0,0,1,0,0,0,0,0,1,1,1,1,1,1,1,0,0,0,0,0,0,0,0,0,0,0,0,0,0,0,0,0,0,0},
{0,0,0,0,0,0,0,0,0,0,0,0,0,0,0,0,0,0,0,0,0,0,0,1,0,0,0,0,0,0,0,0,0,0,0,0,0,0,0,0,0,0,1,0,0,0,0,0,0,0,0,0,0,1,0,0,0,0,1,1,0,0,0,0,0,0,0,1,1,0,0,0,0,0,0,0,0,0,0,0,0,0,0,0,1,0,0,0,0,0,0,0,0,0,0,1,0,0,0,0,1,1,0,0,0,0,0,0,0,1,1,0,0,0,0,0,0,0,0,0,0,0,0,0,0,0,0,0},
{0,0,0,0,0,0,0,0,0,0,0,0,0,0,0,0,0,0,0,0,0,0,0,1,0,0,0,0,0,0,0,0,0,0,0,0,0,0,0,0,0,0,1,0,0,0,0,0,0,0,0,0,0,1,0,0,1,1,0,0,0,0,0,0,0,0,0,0,0,1,1,0,0,0,0,0,0,0,0,0,0,0,0,0,1,0,0,0,0,0,0,0,0,0,0,1,0,0,1,1,0,0,0,0,0,0,0,0,0,0,0,1,1,0,0,0,0,0,0,0,0,0,0,0,0,0,0,0},
{0,0,0,0,0,0,0,0,0,0,0,0,0,0,0,0,0,0,0,0,0,0,0,1,0,0,0,0,0,0,0,0,0,0,0,0,0,0,0,0,0,0,1,0,0,0,0,0,0,0,0,0,0,1,0,1,0,0,0,0,0,0,0,0,0,0,0,0,0,0,0,1,0,0,0,0,0,0,0,0,0,0,0,0,1,0,0,0,0,0,0,0,0,0,0,1,0,1,0,0,0,0,0,0,0,0,0,0,0,0,0,0,0,1,0,0,0,0,0,0,0,0,0,0,0,0,0,0},
{0,0,0,0,0,0,0,0,0,0,0,0,0,0,0,0,0,0,0,0,0,0,0,1,0,0,0,0,0,0,0,0,0,0,0,0,0,0,0,0,0,0,1,0,0,0,0,0,0,0,0,0,0,1,1,0,0,0,0,0,0,0,0,0,0,0,0,0,0,0,0,1,0,0,0,0,0,0,0,0,0,0,0,0,1,0,0,0,0,0,0,0,0,0,0,1,0,1,0,0,0,0,0,0,0,0,0,0,0,0,0,0,0,1,0,0,0,0,0,0,0,0,0,0,0,0,0,0},
{0,0,0,0,0,0,0,0,0,0,0,0,0,0,0,0,0,0,0,0,0,0,0,1,0,0,0,0,0,0,0,0,0,0,0,0,0,0,0,0,0,0,1,0,0,0,0,0,0,0,0,0,0,1,0,0,0,0,0,0,0,0,0,0,0,0,0,0,0,0,0,0,1,0,0,0,0,0,0,0,0,0,0,0,1,0,0,0,0,0,0,0,0,0,0,1,1,0,0,0,0,0,0,0,0,0,0,0,0,0,0,0,0,0,1,0,0,0,0,0,0,0,0,0,0,0,0,0},
{0,0,0,0,0,0,0,0,0,0,0,0,0,0,0,0,0,0,0,0,0,0,0,1,0,0,0,0,0,0,0,0,0,0,0,0,0,0,0,0,0,0,1,0,0,0,0,0,0,0,0,0,0,0,0,0,0,0,0,0,0,0,0,0,0,0,0,0,0,0,0,0,1,0,0,0,0,0,0,0,0,0,0,0,1,0,0,0,0,0,0,0,0,0,0,1,1,0,0,0,0,0,0,0,0,0,0,0,0,0,0,0,0,0,1,0,0,0,0,0,0,0,0,0,0,0,0,0},
{0,0,0,0,0,0,0,0,0,0,0,0,0,0,0,0,0,0,0,0,0,0,0,1,0,0,0,0,0,0,0,0,0,0,0,0,0,0,0,0,0,0,1,0,0,0,0,0,0,0,0,0,0,0,0,0,0,0,0,0,0,0,0,0,0,0,0,0,0,0,0,0,0,1,0,0,0,0,0,0,0,0,0,0,1,0,0,0,0,0,0,0,0,0,0,1,0,0,0,0,0,0,0,0,0,0,0,0,0,0,0,0,0,0,0,1,0,0,0,0,0,0,0,0,0,0,0,0},
{0,0,0,0,0,0,0,0,0,0,0,0,0,0,0,0,0,0,0,0,0,0,0,1,0,0,0,0,0,0,0,0,0,0,0,0,0,0,0,0,0,0,1,0,0,0,0,0,0,0,0,0,0,0,0,0,0,0,0,0,0,0,0,0,0,0,0,0,0,0,0,0,0,1,0,0,0,0,0,0,0,0,0,0,1,0,0,0,0,0,0,0,0,0,0,1,0,0,0,0,0,0,0,0,0,0,0,0,0,0,0,0,0,0,0,1,0,0,0,0,0,0,0,0,0,0,0,0},
{0,0,0,0,0,0,0,0,0,0,0,0,0,0,0,0,0,0,0,0,0,0,0,1,0,0,0,0,0,0,0,0,0,0,0,0,0,0,0,0,0,0,1,0,0,0,0,0,0,0,0,0,0,0,0,0,0,0,0,0,0,0,0,0,0,0,0,0,0,0,0,0,0,1,0,0,0,0,0,0,0,0,0,0,1,0,0,0,0,0,0,0,0,0,0,1,0,0,0,0,0,0,0,0,0,0,0,0,0,0,0,0,0,0,0,1,0,0,0,0,0,0,0,0,0,0,0,0},
{0,0,0,0,0,0,0,0,0,0,0,0,0,0,0,0,0,0,0,0,0,0,0,1,0,0,0,0,0,0,0,0,0,0,0,0,0,0,0,0,0,0,1,0,0,0,0,0,0,0,0,0,0,0,0,0,0,0,0,0,0,0,0,0,0,0,0,0,0,0,0,0,0,1,0,0,0,0,0,0,0,0,0,0,1,0,0,0,0,0,0,0,0,0,0,1,0,0,0,0,0,0,0,0,0,0,0,0,0,0,0,0,0,0,0,1,0,0,0,0,0,0,0,0,0,0,0,0},
{0,0,0,0,0,0,0,0,0,0,0,0,0,0,0,0,0,0,0,0,0,0,0,1,0,0,0,0,0,0,0,0,0,0,0,0,0,0,0,0,0,0,1,0,0,0,0,0,0,0,0,0,0,1,0,0,0,0,0,0,0,0,0,0,0,0,0,0,0,0,0,0,0,1,0,0,0,0,0,0,0,0,0,0,1,0,0,0,0,0,0,0,0,0,0,1,0,0,0,0,0,0,0,0,0,0,0,0,0,0,0,0,0,0,0,1,0,0,0,0,0,0,0,0,0,0,0,0},
{0,0,0,0,0,0,0,0,0,0,0,0,0,0,0,0,0,0,0,0,0,0,0,1,0,0,0,0,0,0,0,0,0,0,0,0,0,0,0,0,0,0,1,0,0,0,0,0,0,0,0,0,0,1,0,0,0,0,0,0,0,0,0,0,0,0,0,0,0,0,0,0,0,1,0,0,0,0,0,0,0,0,0,0,1,0,0,0,0,0,0,0,0,0,0,1,0,0,0,0,0,0,0,0,0,0,0,0,0,0,0,0,0,0,0,1,0,0,0,0,0,0,0,0,0,0,0,0},
{0,0,0,0,0,0,0,0,0,0,0,0,0,0,0,0,0,0,0,0,0,0,0,1,0,0,0,0,0,0,0,0,0,0,0,0,0,0,0,0,0,0,1,0,0,0,0,0,0,0,0,0,0,0,1,0,0,0,0,0,0,0,0,0,0,0,0,0,0,0,0,0,1,0,0,0,0,0,0,0,0,0,0,0,1,0,0,0,0,0,0,0,0,0,0,0,1,0,0,0,0,0,0,0,0,0,0,0,0,0,0,0,0,0,1,0,0,0,0,0,0,0,0,0,0,0,0,0},
{0,0,0,0,0,0,0,0,0,0,0,0,0,0,0,0,0,0,0,0,0,0,0,1,0,0,0,0,0,0,0,0,0,0,0,0,0,0,0,0,0,0,1,0,0,0,0,0,0,0,0,0,0,0,1,0,0,0,0,0,0,0,0,0,0,0,0,0,0,0,0,0,1,0,0,0,0,0,0,0,0,0,0,0,1,0,0,0,0,0,0,0,0,0,0,0,1,0,0,0,0,0,0,0,0,0,0,0,0,0,0,0,0,0,1,0,0,0,0,0,0,0,0,0,0,0,0,0},
{0,0,0,0,0,0,0,0,0,0,0,0,0,0,0,0,0,0,0,0,0,0,0,1,0,0,0,0,0,0,0,0,0,0,0,0,0,0,0,0,0,0,1,0,0,0,0,0,0,0,0,0,0,0,0,1,0,0,0,0,0,0,0,0,0,0,0,0,0,0,0,1,0,0,0,0,0,0,0,0,0,0,0,0,1,0,0,0,0,0,0,0,0,0,0,0,0,1,0,0,0,0,0,0,0,0,0,0,0,0,0,0,0,1,0,0,0,0,0,0,0,0,0,0,0,0,0,0},
{0,0,0,0,0,0,0,0,0,0,0,0,0,0,0,0,0,0,0,0,0,0,0,1,0,0,0,0,0,0,0,0,0,0,0,0,0,0,0,0,0,0,1,0,0,0,0,0,0,0,0,0,0,0,0,1,0,0,0,0,0,0,0,0,0,0,0,0,0,0,0,1,0,0,0,0,0,0,0,0,0,0,0,0,1,0,0,0,0,0,0,0,0,0,0,0,0,1,0,0,0,0,0,0,0,0,0,0,0,0,0,0,0,1,0,0,0,0,0,0,0,0,0,0,0,0,0,0},
{0,0,0,0,0,0,0,0,0,0,0,0,0,0,0,0,0,0,0,0,0,0,0,1,0,0,0,0,0,0,0,0,0,0,0,0,0,0,0,0,0,0,1,0,0,0,0,0,0,0,0,0,0,0,0,0,1,1,0,0,0,0,0,0,0,0,0,0,0,1,1,0,0,0,0,0,0,0,0,0,0,0,0,0,1,0,0,0,0,0,0,0,0,0,0,0,0,0,1,1,0,0,0,0,0,0,0,0,0,0,0,1,1,0,0,0,0,0,0,0,0,0,0,0,0,0,0,0},
{0,0,0,0,0,0,0,0,0,0,0,0,0,0,0,0,0,0,0,0,0,0,0,1,0,0,0,0,0,0,0,0,0,0,0,0,0,0,0,0,0,0,1,0,0,0,0,0,0,0,0,0,0,0,0,0,0,0,1,1,0,0,0,0,0,0,0,1,1,0,0,0,0,0,0,0,0,0,0,0,0,0,0,0,1,0,0,0,0,0,0,0,0,0,0,0,0,0,0,0,1,1,0,0,0,0,0,0,0,1,1,0,0,0,0,0,0,0,0,0,0,0,0,0,0,0,0,0},
{0,0,0,0,0,0,0,0,0,0,0,0,0,0,0,0,0,0,0,0,0,0,0,1,0,0,0,0,0,0,0,0,0,0,0,0,0,0,0,0,0,0,1,0,0,0,0,0,0,0,0,0,0,0,0,0,0,0,0,0,1,1,1,1,1,1,1,0,0,0,0,0,0,0,0,0,0,0,0,0,0,0,0,0,1,0,0,0,0,0,0,0,0,0,0,0,0,0,0,0,0,0,1,1,1,1,1,1,1,0,0,0,0,0,0,0,0,0,0,0,0,0,0,0,0,0,0,0},
{0,0,0,0,0,0,0,0,0,0,0,0,0,0,0,0,0,0,0,0,0,0,0,1,0,0,0,0,0,0,0,0,0,0,0,0,0,0,0,0,0,0,1,0,0,0,0,0,0,0,0,0,0,0,0,0,0,0,0,0,0,0,0,0,0,0,0,0,0,0,0,0,0,0,0,0,0,0,0,0,0,0,0,0,1,0,0,0,0,0,0,0,0,0,0,0,0,0,0,0,0,0,0,0,0,0,0,0,0,0,0,0,0,0,0,0,0,0,0,0,0,0,0,0,0,0,0,0},
{0,0,0,0,0,0,0,0,0,0,0,0,0,0,0,0,0,0,0,0,0,0,0,1,0,0,0,0,0,0,0,0,0,0,0,0,0,0,0,0,0,0,1,0,0,0,0,0,0,0,0,0,0,0,0,0,0,0,0,0,0,0,0,0,0,0,0,0,0,0,0,0,0,0,0,0,0,0,0,0,0,0,0,0,1,0,0,0,0,0,0,0,0,0,0,0,0,0,0,0,0,0,0,0,0,0,0,0,0,0,0,0,0,0,0,0,0,0,0,0,0,0,0,0,0,0,0,0},
{0,0,0,0,0,0,0,0,0,0,0,0,0,0,0,0,0,0,0,0,0,0,0,0,0,0,0,0,0,0,0,0,0,0,0,0,0,0,0,0,0,0,1,0,0,0,0,0,0,0,0,0,0,0,0,0,0,0,0,0,0,0,0,0,0,0,0,0,0,0,0,0,0,0,0,0,0,0,0,0,0,0,0,0,1,0,0,0,0,0,0,0,0,0,0,0,0,0,0,0,0,0,0,0,0,0,0,0,0,0,0,0,0,0,0,0,0,0,0,0,0,0,0,0,0,0,0,0},
{0,0,0,0,0,0,0,0,0,0,0,0,0,0,0,0,0,0,0,0,0,0,0,0,0,0,0,0,0,0,0,0,0,0,0,0,0,0,0,0,0,0,1,0,0,0,0,0,0,0,0,0,0,0,0,0,0,0,0,0,0,0,0,0,0,0,0,0,0,0,0,0,0,0,0,0,0,0,0,0,0,0,0,0,1,0,0,0,0,0,0,0,0,0,0,0,0,0,0,0,0,0,0,0,0,0,0,0,0,0,0,0,0,0,0,0,0,0,0,0,0,0,0,0,0,0,0,0},
{0,0,0,0,0,0,0,0,0,0,0,0,0,0,0,0,0,0,0,0,0,0,0,0,0,0,0,0,0,0,0,0,0,0,0,0,0,0,0,0,0,0,1,0,0,0,0,0,0,0,0,0,0,0,0,0,0,0,0,0,0,0,0,0,0,0,0,0,0,0,0,0,0,0,0,0,0,0,0,0,0,0,0,0,1,0,0,0,0,0,0,0,0,0,0,0,0,0,0,0,0,0,0,0,0,0,0,0,0,0,0,0,0,0,0,0,0,0,0,0,0,0,0,0,0,0,0,0},
{0,0,0,0,0,0,0,0,0,0,0,0,0,0,0,0,0,0,0,0,0,0,0,0,0,0,0,0,0,0,0,0,0,0,0,0,0,0,0,0,0,0,1,0,0,0,0,0,0,0,0,0,0,0,0,0,0,0,0,0,0,0,0,0,0,0,0,0,0,0,0,0,0,0,0,0,0,0,0,0,0,0,0,0,1,0,0,0,0,0,0,0,0,0,0,0,0,0,0,0,0,0,0,0,0,0,0,0,0,0,0,0,0,0,0,0,0,0,0,0,0,0,0,0,0,0,0,0},
{0,0,0,0,0,0,0,0,0,0,0,0,0,0,0,0,0,0,0,0,0,0,0,0,0,0,0,0,0,0,0,0,0,0,0,0,0,0,0,0,0,0,1,0,0,0,0,0,0,0,0,0,0,0,0,0,0,0,0,0,0,0,0,0,0,0,0,0,0,0,0,0,0,0,0,0,0,0,0,0,0,0,0,0,1,0,0,0,0,0,0,0,0,0,0,0,0,0,0,0,0,0,0,0,0,0,0,0,0,0,0,0,0,0,0,0,0,0,0,0,0,0,0,0,0,0,0,0},
{0,0,0,0,0,0,0,0,0,0,0,0,0,0,0,0,0,0,0,0,0,0,0,0,0,0,0,0,0,0,0,0,0,0,0,0,0,0,0,0,0,0,1,0,0,0,0,0,0,0,0,0,0,0,0,0,0,0,0,0,0,0,0,0,0,0,0,0,0,0,0,0,0,0,0,0,0,0,0,0,0,0,0,0,1,0,0,0,0,0,0,0,0,0,0,0,0,0,0,0,0,0,0,0,0,0,0,0,0,0,0,0,0,0,0,0,0,0,0,0,0,0,0,0,0,0,0,0},
{0,0,0,0,0,0,0,0,0,0,0,0,0,0,0,0,0,0,0,0,0,0,0,0,0,0,0,0,0,0,0,0,0,0,0,0,0,0,0,0,0,0,1,0,0,0,0,0,0,0,0,0,0,0,0,0,0,0,0,0,0,0,0,0,0,0,0,0,0,0,0,0,0,0,0,0,0,0,0,0,0,0,0,0,1,0,0,0,0,0,0,0,0,0,0,0,0,0,0,0,0,0,0,0,0,0,0,0,0,0,0,0,0,0,0,0,0,0,0,0,0,0,0,0,0,0,0,0},
{0,0,0,0,0,0,0,0,0,0,0,0,0,0,0,0,0,0,0,0,0,0,0,0,0,0,0,0,0,0,0,0,0,0,0,0,0,0,0,0,0,0,1,0,0,0,0,0,0,0,0,0,0,0,0,0,0,0,0,0,0,0,0,0,0,0,0,0,0,0,0,0,0,0,0,0,0,0,0,0,0,0,0,0,1,0,0,0,0,0,0,0,0,0,0,0,0,0,0,0,0,0,0,0,0,0,0,0,0,0,0,0,0,0,0,0,0,0,0,0,0,0,0,0,0,0,0,0},
{1,1,1,1,1,1,1,1,1,1,1,1,1,1,1,1,1,1,1,1,1,1,1,1,1,1,1,1,1,1,1,1,1,1,1,1,1,1,1,1,1,1,1,1,1,1,1,1,1,1,1,1,1,1,1,1,1,1,1,1,1,1,1,1,1,1,1,1,1,1,1,1,1,1,1,1,1,1,1,1,1,1,1,1,1,1,1,1,1,1,1,1,1,1,1,1,1,1,1,1,1,1,1,1,1,1,1,1,1,1,1,1,1,1,1,1,1,1,1,1,1,1,1,1,1,1,1,1},
{0,0,0,0,0,0,0,0,0,0,0,0,0,0,0,0,0,0,0,0,0,0,0,0,0,0,0,0,0,0,0,0,0,0,0,0,0,0,0,0,0,0,1,0,0,0,0,0,0,0,0,0,0,0,0,0,0,0,0,0,0,0,0,0,0,0,0,0,0,0,0,0,0,0,0,0,0,0,0,0,0,0,0,0,1,0,0,0,0,0,0,0,0,0,0,0,0,0,0,0,0,0,0,0,0,0,0,0,0,0,0,0,0,0,0,0,0,0,0,0,0,0,0,0,0,0,0,0},
{0,0,0,0,0,0,0,0,0,0,0,0,0,0,0,0,0,0,0,0,0,0,0,0,0,0,0,0,0,0,0,0,0,0,0,0,0,0,0,0,0,0,1,0,0,0,0,0,0,0,0,0,0,0,0,0,0,0,0,0,0,0,0,0,0,0,0,0,0,0,0,0,0,0,0,0,0,0,0,0,0,0,0,0,1,0,0,0,0,0,0,0,0,0,0,0,0,0,0,0,0,0,0,0,0,0,0,0,0,0,0,0,0,0,0,0,0,0,0,0,0,0,0,0,0,0,0,0},
{0,0,0,0,0,0,0,0,0,0,0,0,0,0,0,0,0,0,0,0,0,0,0,0,0,0,0,0,0,0,0,0,0,0,0,0,0,0,0,0,0,0,1,0,0,0,0,0,0,0,0,0,0,0,0,0,0,0,0,0,0,0,0,0,0,0,0,0,0,0,0,0,0,0,0,0,0,0,0,0,0,0,0,0,1,0,0,0,0,0,0,0,0,0,0,0,0,0,0,0,0,0,0,0,0,0,0,0,0,0,0,0,0,0,0,0,0,0,0,0,0,0,0,0,0,0,0,0},
{0,0,0,0,0,0,0,0,0,0,0,0,0,0,0,0,0,0,0,0,0,0,0,0,0,0,0,0,0,0,0,0,0,0,0,0,0,0,0,0,0,0,1,0,0,0,0,0,0,0,0,0,0,0,0,0,0,0,0,0,0,0,0,0,0,0,0,0,0,0,0,0,0,0,0,0,0,0,0,0,0,0,0,0,1,0,0,0,0,0,0,0,0,0,0,0,0,0,0,0,0,0,0,0,0,0,0,0,0,0,0,0,0,0,0,0,0,0,0,0,0,0,0,0,0,0,0,0},
{0,0,0,0,0,0,0,0,0,0,0,0,0,0,0,0,0,0,0,0,0,0,0,0,0,0,0,0,0,0,0,0,0,0,0,0,0,0,0,0,0,0,1,0,0,0,0,0,0,0,0,0,0,0,0,0,0,0,0,0,0,0,0,0,0,0,0,0,0,0,0,0,0,0,0,0,0,0,0,0,0,0,0,0,1,0,0,0,0,0,0,0,0,0,0,0,0,0,0,0,0,0,0,0,0,0,0,0,0,0,0,0,0,0,0,0,0,0,0,0,0,0,0,0,0,0,0,0},
{0,0,0,0,0,0,0,0,0,0,0,0,0,0,0,0,0,0,0,0,0,0,0,0,0,0,0,0,0,0,0,0,0,0,0,0,0,0,0,0,0,0,1,0,0,0,0,0,0,0,0,0,0,0,0,0,0,0,0,0,0,0,0,0,0,0,0,0,0,0,0,0,0,0,0,0,0,0,0,0,0,0,0,0,1,0,0,0,0,0,0,0,0,0,0,0,0,0,0,0,0,0,0,0,0,0,0,0,0,0,0,0,0,0,0,0,0,0,0,0,0,0,0,0,0,0,0,0},
{0,0,0,0,0,0,0,0,0,0,0,0,0,0,0,0,0,0,0,0,0,0,0,0,0,0,0,0,0,0,0,0,0,0,0,0,0,0,0,0,0,0,1,0,0,0,0,0,0,0,0,0,0,0,0,0,0,0,0,0,0,0,0,0,0,0,0,0,0,0,0,0,0,0,0,0,0,0,0,0,0,0,0,0,1,0,0,0,0,0,0,0,0,0,0,0,0,0,0,0,0,0,0,0,0,0,0,0,0,0,0,0,0,0,0,0,0,0,0,0,0,0,0,0,0,0,0,0},
{0,0,0,0,0,0,0,0,0,0,0,0,0,0,0,0,0,0,0,0,0,0,0,0,0,0,0,0,0,0,0,0,0,0,0,0,0,0,0,0,0,0,1,0,0,0,0,0,0,0,0,0,0,0,0,0,0,0,0,0,0,0,0,0,0,0,0,0,0,0,0,0,0,0,0,0,0,0,0,0,0,0,0,0,1,0,0,0,0,0,0,0,0,0,0,0,0,0,0,0,0,0,0,0,0,0,0,0,0,0,0,0,0,0,0,0,0,0,0,0,0,0,0,0,0,0,0,0},
{0,0,0,0,0,0,0,0,0,0,0,0,0,0,0,0,0,0,0,1,0,0,0,0,0,0,0,0,0,0,0,0,0,0,0,0,0,0,0,0,0,0,1,0,0,0,0,0,0,0,0,0,0,0,0,0,0,0,0,0,0,1,1,1,1,1,1,0,0,0,0,0,0,0,0,0,0,0,0,0,0,0,0,0,1,0,0,0,0,0,0,0,0,0,0,0,0,0,0,0,0,0,0,1,1,1,1,1,1,0,0,0,0,0,0,0,0,0,0,0,0,0,0,0,0,0,0,0},
{0,0,0,0,0,0,0,0,0,0,0,0,0,0,0,0,0,0,1,1,0,0,0,0,0,0,0,0,0,0,0,0,0,0,0,0,0,0,0,0,0,0,1,0,0,0,0,0,0,0,0,0,0,0,0,0,0,0,0,1,1,0,0,0,0,0,0,1,1,0,0,0,0,0,0,0,0,0,0,0,0,0,0,0,1,0,0,0,0,0,0,0,0,0,0,0,0,0,0,0,0,1,1,0,0,0,0,0,0,1,1,0,0,0,0,0,0,0,0,0,0,0,0,0,0,0,0,0},
{0,0,0,0,0,0,0,0,0,0,0,0,0,0,0,0,0,1,0,1,0,0,0,0,0,0,0,0,0,0,0,0,0,0,0,0,0,0,0,0,0,0,1,0,0,0,0,0,0,0,0,0,0,0,0,0,0,1,1,0,0,0,0,0,0,0,0,0,0,1,1,0,0,0,0,0,0,0,0,0,0,0,0,0,1,0,0,0,0,0,0,0,0,0,0,0,0,0,0,1,1,0,0,0,0,0,0,0,0,0,0,1,1,0,0,0,0,0,0,0,0,0,0,0,0,0,0,0},
{0,0,0,0,0,0,0,0,0,0,0,0,0,0,0,0,1,0,0,1,0,0,0,0,0,0,0,0,0,0,0,0,0,0,0,0,0,0,0,0,0,0,1,0,0,0,0,0,0,0,0,0,0,0,0,0,1,0,0,0,0,0,0,0,0,0,0,0,0,0,0,1,0,0,0,0,0,0,0,0,0,0,0,0,1,0,0,0,0,0,0,0,0,0,0,0,0,0,1,0,0,0,0,0,0,0,0,0,0,0,0,0,0,1,0,0,0,0,0,0,0,0,0,0,0,0,0,0},
{0,0,0,0,0,0,0,0,0,0,0,0,0,0,0,1,0,0,0,1,0,0,0,0,0,0,0,0,0,0,0,0,0,0,0,0,0,0,0,0,0,0,1,0,0,0,0,0,0,0,0,0,0,0,0,0,1,0,0,0,0,0,0,0,0,0,0,0,0,0,0,1,0,0,0,0,0,0,0,0,0,0,0,0,1,0,0,0,0,0,0,0,0,0,0,0,0,0,1,0,0,0,0,0,0,0,0,0,0,0,0,0,0,1,0,0,0,0,0,0,0,0,0,0,0,0,0,0},
{0,0,0,0,0,0,0,0,0,0,0,0,0,0,1,0,0,0,0,1,0,0,0,0,0,0,0,0,0,0,0,0,0,0,0,0,0,0,0,0,0,0,1,0,0,0,0,0,0,0,0,0,0,0,0,1,0,0,0,0,0,0,0,0,0,0,0,0,0,0,0,0,1,0,0,0,0,0,0,0,0,0,0,0,1,0,0,0,0,0,0,0,0,0,0,0,0,1,0,0,0,0,0,0,0,0,0,0,0,0,0,0,0,0,1,0,0,0,0,0,0,0,0,0,0,0,0,0},
{0,0,0,0,0,0,0,0,0,0,0,0,0,1,0,0,0,0,0,1,0,0,0,0,0,0,0,0,0,0,0,0,0,0,0,0,0,0,0,0,0,0,1,0,0,0,0,0,0,0,0,0,0,0,0,1,0,0,0,0,0,0,0,0,0,0,0,0,0,0,0,0,1,0,0,0,0,0,0,0,0,0,0,0,1,0,0,0,0,0,0,0,0,0,0,0,0,1,0,0,0,0,0,0,0,0,0,0,0,0,0,0,0,0,1,0,0,0,0,0,0,0,0,0,0,0,0,0},
{0,0,0,0,0,0,0,0,0,0,0,0,1,0,0,0,0,0,0,1,0,0,0,0,0,0,0,0,0,0,0,0,0,0,0,0,0,0,0,0,0,0,1,0,0,0,0,0,0,0,0,0,0,0,1,0,0,0,0,0,0,0,0,0,0,0,0,0,0,0,0,0,0,1,0,0,0,0,0,0,0,0,0,0,1,0,0,0,0,0,0,0,0,0,0,0,1,0,0,0,0,0,0,0,0,0,0,0,0,0,0,0,0,0,0,1,0,0,0,0,0,0,0,0,0,0,0,0},
{0,0,0,0,0,0,0,0,0,0,0,1,0,0,0,0,0,0,0,1,0,0,0,0,0,0,0,0,0,0,0,0,0,0,0,0,0,0,0,0,0,0,1,0,0,0,0,0,0,0,0,0,0,0,1,0,0,0,0,0,0,0,0,0,0,0,0,0,0,0,0,0,0,1,0,0,0,0,0,0,0,0,0,0,1,0,0,0,0,0,0,0,0,0,0,0,1,0,0,0,0,0,0,0,0,0,0,0,0,0,0,0,0,0,0,1,0,0,0,0,0,0,0,0,0,0,0,0},
{0,0,0,0,0,0,0,0,0,0,0,0,0,0,0,0,0,0,0,1,0,0,0,0,0,0,0,0,0,0,0,0,0,0,0,0,0,0,0,0,0,0,1,0,0,0,0,0,0,0,0,0,0,0,0,0,0,0,0,0,0,0,0,0,0,0,0,0,0,0,0,0,0,1,0,0,0,0,0,0,0,0,0,0,1,0,0,0,0,0,0,0,0,0,0,0,0,0,0,0,0,0,0,0,0,0,0,0,0,0,0,0,0,0,0,1,0,0,0,0,0,0,0,0,0,0,0,0},
{0,0,0,0,0,0,0,0,0,0,0,0,0,0,0,0,0,0,0,1,0,0,0,0,0,0,0,0,0,0,0,0,0,0,0,0,0,0,0,0,0,0,1,0,0,0,0,0,0,0,0,0,0,0,0,0,0,0,0,0,0,0,0,0,0,0,0,0,0,0,0,0,0,1,0,0,0,0,0,0,0,0,0,0,1,0,0,0,0,0,0,0,0,0,0,0,0,0,0,0,0,0,0,0,0,0,0,0,0,0,0,0,0,0,0,1,0,0,0,0,0,0,0,0,0,0,0,0},
{0,0,0,0,0,0,0,0,0,0,0,0,0,0,0,0,0,0,0,1,0,0,0,0,0,0,0,0,0,0,0,0,0,0,0,0,0,0,0,0,0,0,1,0,0,0,0,0,0,0,0,0,0,0,0,0,0,0,0,0,0,0,0,0,0,0,0,0,0,0,0,0,0,1,0,0,0,0,0,0,0,0,0,0,1,0,0,0,0,0,0,0,0,0,0,0,0,0,0,0,0,0,0,0,0,0,0,0,0,0,0,0,0,0,1,0,0,0,0,0,0,0,0,0,0,0,0,0},
{0,0,0,0,0,0,0,0,0,0,0,0,0,0,0,0,0,0,0,1,0,0,0,0,0,0,0,0,0,0,0,0,0,0,0,0,0,0,0,0,0,0,1,0,0,0,0,0,0,0,0,0,0,0,0,0,0,0,0,0,0,0,0,0,0,0,0,0,0,0,0,0,0,1,0,0,0,0,0,0,0,0,0,0,1,0,0,0,0,0,0,0,0,0,0,0,0,0,0,0,0,0,0,0,0,0,0,0,0,0,0,0,0,0,1,0,0,0,0,0,0,0,0,0,0,0,0,0},
{0,0,0,0,0,0,0,0,0,0,0,0,0,0,0,0,0,0,0,1,0,0,0,0,0,0,0,0,0,0,0,0,0,0,0,0,0,0,0,0,0,0,1,0,0,0,0,0,0,0,0,0,0,0,0,0,0,0,0,0,0,0,0,0,0,0,0,0,0,0,0,0,0,1,0,0,0,0,0,0,0,0,0,0,1,0,0,0,0,0,0,0,0,0,0,0,0,0,0,0,0,0,0,0,0,0,0,0,0,0,0,0,0,1,0,0,0,0,0,0,0,0,0,0,0,0,0,0},
{0,0,0,0,0,0,0,0,0,0,0,0,0,0,0,0,0,0,0,1,0,0,0,0,0,0,0,0,0,0,0,0,0,0,0,0,0,0,0,0,0,0,1,0,0,0,0,0,0,0,0,0,0,0,0,0,0,0,0,0,0,0,0,0,0,0,0,0,0,0,0,0,0,1,0,0,0,0,0,0,0,0,0,0,1,0,0,0,0,0,0,0,0,0,0,0,0,0,0,0,0,0,0,0,0,0,0,0,0,0,0,0,0,1,0,0,0,0,0,0,0,0,0,0,0,0,0,0},
{0,0,0,0,0,0,0,0,0,0,0,0,0,0,0,0,0,0,0,1,0,0,0,0,0,0,0,0,0,0,0,0,0,0,0,0,0,0,0,0,0,0,1,0,0,0,0,0,0,0,0,0,0,0,0,0,0,0,0,0,0,0,0,0,0,0,0,0,0,0,0,0,0,1,0,0,0,0,0,0,0,0,0,0,1,0,0,0,0,0,0,0,0,0,0,0,0,0,0,0,0,0,0,0,0,0,0,0,0,0,0,0,1,0,0,0,0,0,0,0,0,0,0,0,0,0,0,0},
{0,0,0,0,0,0,0,0,0,0,0,0,0,0,0,0,0,0,0,1,0,0,0,0,0,0,0,0,0,0,0,0,0,0,0,0,0,0,0,0,0,0,1,0,0,0,0,0,0,0,0,0,0,0,0,0,0,0,0,0,0,0,0,0,0,0,0,0,0,0,0,0,0,1,0,0,0,0,0,0,0,0,0,0,1,0,0,0,0,0,0,0,0,0,0,0,0,0,0,0,0,0,0,0,0,0,0,0,0,0,0,1,0,0,0,0,0,0,0,0,0,0,0,0,0,0,0,0},
{0,0,0,0,0,0,0,0,0,0,0,0,0,0,0,0,0,0,0,1,0,0,0,0,0,0,0,0,0,0,0,0,0,0,0,0,0,0,0,0,0,0,1,0,0,0,0,0,0,0,0,0,0,0,0,0,0,0,0,0,0,0,0,0,0,0,0,0,0,0,0,0,1,0,0,0,0,0,0,0,0,0,0,0,1,0,0,0,0,0,0,0,0,0,0,0,0,0,0,0,0,0,0,0,0,0,0,0,0,1,1,0,0,0,0,0,0,0,0,0,0,0,0,0,0,0,0,0},
{0,0,0,0,0,0,0,0,0,0,0,0,0,0,0,0,0,0,0,1,0,0,0,0,0,0,0,0,0,0,0,0,0,0,0,0,0,0,0,0,0,0,1,0,0,0,0,0,0,0,0,0,0,0,0,0,0,0,0,0,0,0,0,0,0,0,0,0,0,0,0,1,0,0,0,0,0,0,0,0,0,0,0,0,1,0,0,0,0,0,0,0,0,0,0,0,0,0,0,0,0,0,0,0,0,0,1,1,1,0,0,0,0,0,0,0,0,0,0,0,0,0,0,0,0,0,0,0},
{0,0,0,0,0,0,0,0,0,0,0,0,0,0,0,0,0,0,0,1,0,0,0,0,0,0,0,0,0,0,0,0,0,0,0,0,0,0,0,0,0,0,1,0,0,0,0,0,0,0,0,0,0,0,0,0,0,0,0,0,0,0,0,0,0,0,0,0,0,0,1,0,0,0,0,0,0,0,0,0,0,0,0,0,1,0,0,0,0,0,0,0,0,0,0,0,0,0,0,0,0,0,0,0,0,0,0,0,0,1,1,0,0,0,0,0,0,0,0,0,0,0,0,0,0,0,0,0},
{0,0,0,0,0,0,0,0,0,0,0,0,0,0,0,0,0,0,0,1,0,0,0,0,0,0,0,0,0,0,0,0,0,0,0,0,0,0,0,0,0,0,1,0,0,0,0,0,0,0,0,0,0,0,0,0,0,0,0,0,0,0,0,0,0,0,0,0,0,1,0,0,0,0,0,0,0,0,0,0,0,0,0,0,1,0,0,0,0,0,0,0,0,0,0,0,0,0,0,0,0,0,0,0,0,0,0,0,0,0,0,1,0,0,0,0,0,0,0,0,0,0,0,0,0,0,0,0},
{0,0,0,0,0,0,0,0,0,0,0,0,0,0,0,0,0,0,0,1,0,0,0,0,0,0,0,0,0,0,0,0,0,0,0,0,0,0,0,0,0,0,1,0,0,0,0,0,0,0,0,0,0,0,0,0,0,0,0,0,0,0,0,0,0,0,0,0,1,0,0,0,0,0,0,0,0,0,0,0,0,0,0,0,1,0,0,0,0,0,0,0,0,0,0,0,0,0,0,0,0,0,0,0,0,0,0,0,0,0,0,0,1,0,0,0,0,0,0,0,0,0,0,0,0,0,0,0},
{0,0,0,0,0,0,0,0,0,0,0,0,0,0,0,0,0,0,0,1,0,0,0,0,0,0,0,0,0,0,0,0,0,0,0,0,0,0,0,0,0,0,1,0,0,0,0,0,0,0,0,0,0,0,0,0,0,0,0,0,0,0,0,0,0,0,0,1,0,0,0,0,0,0,0,0,0,0,0,0,0,0,0,0,1,0,0,0,0,0,0,0,0,0,0,0,0,0,0,0,0,0,0,0,0,0,0,0,0,0,0,0,0,1,0,0,0,0,0,0,0,0,0,0,0,0,0,0},
{0,0,0,0,0,0,0,0,0,0,0,0,0,0,0,0,0,0,0,1,0,0,0,0,0,0,0,0,0,0,0,0,0,0,0,0,0,0,0,0,0,0,1,0,0,0,0,0,0,0,0,0,0,0,0,0,0,0,0,0,0,0,0,0,0,0,1,0,0,0,0,0,0,0,0,0,0,0,0,0,0,0,0,0,1,0,0,0,0,0,0,0,0,0,0,0,0,0,0,0,0,0,0,0,0,0,0,0,0,0,0,0,0,1,0,0,0,0,0,0,0,0,0,0,0,0,0,0},
{0,0,0,0,0,0,0,0,0,0,0,0,0,0,0,0,0,0,0,1,0,0,0,0,0,0,0,0,0,0,0,0,0,0,0,0,0,0,0,0,0,0,1,0,0,0,0,0,0,0,0,0,0,0,0,0,0,0,0,0,0,0,0,0,0,1,0,0,0,0,0,0,0,0,0,0,0,0,0,0,0,0,0,0,1,0,0,0,0,0,0,0,0,0,0,0,0,0,0,0,0,0,0,0,0,0,0,0,0,0,0,0,0,0,1,0,0,0,0,0,0,0,0,0,0,0,0,0},
{0,0,0,0,0,0,0,0,0,0,0,0,0,0,0,0,0,0,0,1,0,0,0,0,0,0,0,0,0,0,0,0,0,0,0,0,0,0,0,0,0,0,1,0,0,0,0,0,0,0,0,0,0,0,0,0,0,0,0,0,0,0,0,0,1,0,0,0,0,0,0,0,0,0,0,0,0,0,0,0,0,0,0,0,1,0,0,0,0,0,0,0,0,0,0,0,0,0,0,0,0,0,0,0,0,0,0,0,0,0,0,0,0,0,1,0,0,0,0,0,0,0,0,0,0,0,0,0},
{0,0,0,0,0,0,0,0,0,0,0,0,0,0,0,0,0,0,0,1,0,0,0,0,0,0,0,0,0,0,0,0,0,0,0,0,0,0,0,0,0,0,1,0,0,0,0,0,0,0,0,0,0,0,0,0,0,0,0,0,0,0,0,1,0,0,0,0,0,0,0,0,0,0,0,0,0,0,0,0,0,0,0,0,1,0,0,0,0,0,0,0,0,0,0,0,0,0,0,0,0,0,0,0,0,0,0,0,0,0,0,0,0,0,0,1,0,0,0,0,0,0,0,0,0,0,0,0},
{0,0,0,0,0,0,0,0,0,0,0,0,0,0,0,0,0,0,0,1,0,0,0,0,0,0,0,0,0,0,0,0,0,0,0,0,0,0,0,0,0,0,1,0,0,0,0,0,0,0,0,0,0,0,0,0,0,0,0,0,0,0,1,0,0,0,0,0,0,0,0,0,0,0,0,0,0,0,0,0,0,0,0,0,1,0,0,0,0,0,0,0,0,0,0,0,0,0,0,0,0,0,0,0,0,0,0,0,0,0,0,0,0,0,0,1,0,0,0,0,0,0,0,0,0,0,0,0},
{0,0,0,0,0,0,0,0,0,0,0,0,0,0,0,0,0,0,0,1,0,0,0,0,0,0,0,0,0,0,0,0,0,0,0,0,0,0,0,0,0,0,1,0,0,0,0,0,0,0,0,0,0,0,0,0,0,0,0,0,0,1,0,0,0,0,0,0,0,0,0,0,0,0,0,0,0,0,0,0,0,0,0,0,1,0,0,0,0,0,0,0,0,0,0,0,1,0,0,0,0,0,0,0,0,0,0,0,0,0,0,0,0,0,0,1,0,0,0,0,0,0,0,0,0,0,0,0},
{0,0,0,0,0,0,0,0,0,0,0,0,0,0,0,0,0,0,0,1,0,0,0,0,0,0,0,0,0,0,0,0,0,0,0,0,0,0,0,0,0,0,1,0,0,0,0,0,0,0,0,0,0,0,0,0,0,0,0,0,1,0,0,0,0,0,0,0,0,0,0,0,0,0,0,0,0,0,0,0,0,0,0,0,1,0,0,0,0,0,0,0,0,0,0,0,1,0,0,0,0,0,0,0,0,0,0,0,0,0,0,0,0,0,0,1,0,0,0,0,0,0,0,0,0,0,0,0},
{0,0,0,0,0,0,0,0,0,0,0,0,0,0,0,0,0,0,0,1,0,0,0,0,0,0,0,0,0,0,0,0,0,0,0,0,0,0,0,0,0,0,1,0,0,0,0,0,0,0,0,0,0,0,0,0,0,0,0,1,0,0,0,0,0,0,0,0,0,0,0,0,0,0,0,0,0,0,0,0,0,0,0,0,1,0,0,0,0,0,0,0,0,0,0,0,0,1,0,0,0,0,0,0,0,0,0,0,0,0,0,0,0,0,1,0,0,0,0,0,0,0,0,0,0,0,0,0},
{0,0,0,0,0,0,0,0,0,0,0,0,0,0,0,0,0,0,0,1,0,0,0,0,0,0,0,0,0,0,0,0,0,0,0,0,0,0,0,0,0,0,1,0,0,0,0,0,0,0,0,0,0,0,0,0,0,0,1,0,0,0,0,0,0,0,0,0,0,0,0,0,0,0,0,0,0,0,0,0,0,0,0,0,1,0,0,0,0,0,0,0,0,0,0,0,0,1,0,0,0,0,0,0,0,0,0,0,0,0,0,0,0,0,1,0,0,0,0,0,0,0,0,0,0,0,0,0},
{0,0,0,0,0,0,0,0,0,0,0,0,0,0,0,0,0,0,0,1,0,0,0,0,0,0,0,0,0,0,0,0,0,0,0,0,0,0,0,0,0,0,1,0,0,0,0,0,0,0,0,0,0,0,0,0,0,1,0,0,0,0,0,0,0,0,0,0,0,0,0,0,0,0,0,0,0,0,0,0,0,0,0,0,1,0,0,0,0,0,0,0,0,0,0,0,0,0,1,0,0,0,0,0,0,0,0,0,0,0,0,0,0,1,0,0,0,0,0,0,0,0,0,0,0,0,0,0},
{0,0,0,0,0,0,0,0,0,0,0,0,0,0,0,0,0,0,0,1,0,0,0,0,0,0,0,0,0,0,0,0,0,0,0,0,0,0,0,0,0,0,1,0,0,0,0,0,0,0,0,0,0,0,0,0,1,0,0,0,0,0,0,0,0,0,0,0,0,0,0,0,0,0,0,0,0,0,0,0,0,0,0,0,1,0,0,0,0,0,0,0,0,0,0,0,0,0,1,0,0,0,0,0,0,0,0,0,0,0,0,0,0,1,0,0,0,0,0,0,0,0,0,0,0,0,0,0},
{0,0,0,0,0,0,0,0,0,0,0,0,0,0,0,0,0,0,0,1,0,0,0,0,0,0,0,0,0,0,0,0,0,0,0,0,0,0,0,0,0,0,1,0,0,0,0,0,0,0,0,0,0,0,0,1,0,0,0,0,0,0,0,0,0,0,0,0,0,0,0,0,0,0,0,0,0,0,0,0,0,0,0,0,1,0,0,0,0,0,0,0,0,0,0,0,0,0,0,1,1,0,0,0,0,0,0,0,0,0,0,1,1,0,0,0,0,0,0,0,0,0,0,0,0,0,0,0},
{0,0,0,0,0,0,0,0,0,0,0,0,0,0,0,0,0,0,0,1,0,0,0,0,0,0,0,0,0,0,0,0,0,0,0,0,0,0,0,0,0,0,1,0,0,0,0,0,0,0,0,0,0,0,1,0,0,0,0,0,0,0,0,0,0,0,0,0,0,0,0,0,0,0,0,0,0,0,0,0,0,0,0,0,1,0,0,0,0,0,0,0,0,0,0,0,0,0,0,0,0,1,1,0,0,0,0,0,0,1,1,0,0,0,0,0,0,0,0,0,0,0,0,0,0,0,0,0},
{0,0,0,0,0,0,0,0,0,0,1,1,1,1,1,1,1,1,1,1,1,1,1,1,1,1,1,1,1,0,0,0,0,0,0,0,0,0,0,0,0,0,1,0,0,0,0,0,0,0,0,0,0,0,1,1,1,1,1,1,1,1,1,1,1,1,1,1,1,1,1,1,1,1,0,0,0,0,0,0,0,0,0,0,1,0,0,0,0,0,0,0,0,0,0,0,0,0,0,0,0,0,0,1,1,1,1,1,1,0,0,0,0,0,0,0,0,0,0,0,0,0,0,0,0,0,0,0},
{0,0,0,0,0,0,0,0,0,0,0,0,0,0,0,0,0,0,0,0,0,0,0,0,0,0,0,0,0,0,0,0,0,0,0,0,0,0,0,0,0,0,1,0,0,0,0,0,0,0,0,0,0,0,0,0,0,0,0,0,0,0,0,0,0,0,0,0,0,0,0,0,0,0,0,0,0,0,0,0,0,0,0,0,1,0,0,0,0,0,0,0,0,0,0,0,0,0,0,0,0,0,0,0,0,0,0,0,0,0,0,0,0,0,0,0,0,0,0,0,0,0,0,0,0,0,0,0},
{0,0,0,0,0,0,0,0,0,0,0,0,0,0,0,0,0,0,0,0,0,0,0,0,0,0,0,0,0,0,0,0,0,0,0,0,0,0,0,0,0,0,1,0,0,0,0,0,0,0,0,0,0,0,0,0,0,0,0,0,0,0,0,0,0,0,0,0,0,0,0,0,0,0,0,0,0,0,0,0,0,0,0,0,1,0,0,0,0,0,0,0,0,0,0,0,0,0,0,0,0,0,0,0,0,0,0,0,0,0,0,0,0,0,0,0,0,0,0,0,0,0,0,0,0,0,0,0},
{0,0,0,0,0,0,0,0,0,0,0,0,0,0,0,0,0,0,0,0,0,0,0,0,0,0,0,0,0,0,0,0,0,0,0,0,0,0,0,0,0,0,1,0,0,0,0,0,0,0,0,0,0,0,0,0,0,0,0,0,0,0,0,0,0,0,0,0,0,0,0,0,0,0,0,0,0,0,0,0,0,0,0,0,1,0,0,0,0,0,0,0,0,0,0,0,0,0,0,0,0,0,0,0,0,0,0,0,0,0,0,0,0,0,0,0,0,0,0,0,0,0,0,0,0,0,0,0},
{0,0,0,0,0,0,0,0,0,0,0,0,0,0,0,0,0,0,0,0,0,0,0,0,0,0,0,0,0,0,0,0,0,0,0,0,0,0,0,0,0,0,1,0,0,0,0,0,0,0,0,0,0,0,0,0,0,0,0,0,0,0,0,0,0,0,0,0,0,0,0,0,0,0,0,0,0,0,0,0,0,0,0,0,1,0,0,0,0,0,0,0,0,0,0,0,0,0,0,0,0,0,0,0,0,0,0,0,0,0,0,0,0,0,0,0,0,0,0,0,0,0,0,0,0,0,0,0},
{0,0,0,0,0,0,0,0,0,0,0,0,0,0,0,0,0,0,0,0,0,0,0,0,0,0,0,0,0,0,0,0,0,0,0,0,0,0,0,0,0,0,1,0,0,0,0,0,0,0,0,0,0,0,0,0,0,0,0,0,0,0,0,0,0,0,0,0,0,0,0,0,0,0,0,0,0,0,0,0,0,0,0,0,1,0,0,0,0,0,0,0,0,0,0,0,0,0,0,0,0,0,0,0,0,0,0,0,0,0,0,0,0,0,0,0,0,0,0,0,0,0,0,0,0,0,0,0},
{0,0,0,0,0,0,0,0,0,0,0,0,0,0,0,0,0,0,0,0,0,0,0,0,0,0,0,0,0,0,0,0,0,0,0,0,0,0,0,0,0,0,1,0,0,0,0,0,0,0,0,0,0,0,0,0,0,0,0,0,0,0,0,0,0,0,0,0,0,0,0,0,0,0,0,0,0,0,0,0,0,0,0,0,1,0,0,0,0,0,0,0,0,0,0,0,0,0,0,0,0,0,0,0,0,0,0,0,0,0,0,0,0,0,0,0,0,0,0,0,0,0,0,0,0,0,0,0},
{0,0,0,0,0,0,0,0,0,0,0,0,0,0,0,0,0,0,0,0,0,0,0,0,0,0,0,0,0,0,0,0,0,0,0,0,0,0,0,0,0,0,1,0,0,0,0,0,0,0,0,0,0,0,0,0,0,0,0,0,0,0,0,0,0,0,0,0,0,0,0,0,0,0,0,0,0,0,0,0,0,0,0,0,1,0,0,0,0,0,0,0,0,0,0,0,0,0,0,0,0,0,0,0,0,0,0,0,0,0,0,0,0,0,0,0,0,0,0,0,0,0,0,0,0,0,0,0},
{0,0,0,0,0,0,0,0,0,0,0,0,0,0,0,0,0,0,0,0,0,0,0,0,0,0,0,0,0,0,0,0,0,0,0,0,0,0,0,0,0,0,1,0,0,0,0,0,0,0,0,0,0,0,0,0,0,0,0,0,0,0,0,0,0,0,0,0,0,0,0,0,0,0,0,0,0,0,0,0,0,0,0,0,1,0,0,0,0,0,0,0,0,0,0,0,0,0,0,0,0,0,0,0,0,0,0,0,0,0,0,0,0,0,0,0,0,0,0,0,0,0,0,0,0,0,0,0},
};
uint16_t cursor_x = 64; // start in the middle
uint16_t cursor_y = 80;
uint16_t time = 0; // variable to debounce the button
/* USER CODE END PV */

void SystemClock_Config(void);
void PeriphCommonClock_Config(void);
static void MX_GPIO_Init(void);
static void MX_ADC1_Init(void);
static void MX_ADC2_Init(void);
static void MX_I2C1_Init(void);
static void MX_SPI1_Init(void);
static void MX_TIM16_Init(void);
/* USER CODE BEGIN PFP */
void CharLCD_Write_Nibble (uint8_t nibble, uint8_t dc);
void CharLCD_Send_Cmd(uint8_t cmd);
void CharLCD_Send_Data(uint8_t data);
void CharLCD_Init();
void CharLCD_Write_String(char *str);
void CharLCD_Set_Cursor(uint8_t row, uint8_t column);
void CharLCD_Clear(void);
void ST7735_WriteData(uint8_t data[], uint16_t size);
void ST7735_WriteCommand(uint8_t cmd);
void ST7735_Init(void);
void ST7735_SetAddressWindow(uint16_t xStart, uint16_t yStart, uint16_t xEnd, uint16_t yEnd);
void ST7735_DrawPixel(uint8_t x, uint8_t y, uint16_t color);
void ST7735_StartScreen(void);
/* USER CODE END PFP */

int main(void)
{

  /* MCU Configuration--------------------------------------------------------*/

  /* Reset of all peripherals, Initializes the Flash interface and the Systick. */
  HAL_Init();

  /* Configure the system clock */
  SystemClock_Config();

  /* Configure the peripherals common clocks */
  PeriphCommonClock_Config();

  /* Initialize all configured peripherals */
  MX_GPIO_Init();
  MX_ADC1_Init();
  MX_ADC2_Init();
  MX_I2C1_Init();
  MX_SPI1_Init();
  MX_TIM16_Init();
  /* USER CODE BEGIN 2 */
  HAL_TIM_Base_Start_IT(&htim16); // Start Timer16

  CharLCD_Init(); // Initialize the character LCD
  ST7735_Init(); // Initialize the color LCD
  ST7735_StartScreen(); // Draw the initial screen
  /* USER CODE END 2 */

  /* Infinite loop */
  while (1)
  {

  }
}

void SystemClock_Config(void)
{
  RCC_OscInitTypeDef RCC_OscInitStruct = {0};
  RCC_ClkInitTypeDef RCC_ClkInitStruct = {0};

  /** Configure the main internal regulator output voltage
  */
  if (HAL_PWREx_ControlVoltageScaling(PWR_REGULATOR_VOLTAGE_SCALE1) != HAL_OK)
  {
    Error_Handler();
  }

  /** Initializes the RCC Oscillators according to the specified parameters
  * in the RCC_OscInitTypeDef structure.
  */
  RCC_OscInitStruct.OscillatorType = RCC_OSCILLATORTYPE_HSI;
  RCC_OscInitStruct.HSIState = RCC_HSI_ON;
  RCC_OscInitStruct.HSICalibrationValue = RCC_HSICALIBRATION_DEFAULT;
  RCC_OscInitStruct.PLL.PLLState = RCC_PLL_ON;
  RCC_OscInitStruct.PLL.PLLSource = RCC_PLLSOURCE_HSI;
  RCC_OscInitStruct.PLL.PLLM = 1;
  RCC_OscInitStruct.PLL.PLLN = 10;
  RCC_OscInitStruct.PLL.PLLP = RCC_PLLP_DIV7;
  RCC_OscInitStruct.PLL.PLLQ = RCC_PLLQ_DIV2;
  RCC_OscInitStruct.PLL.PLLR = RCC_PLLR_DIV2;
  if (HAL_RCC_OscConfig(&RCC_OscInitStruct) != HAL_OK)
  {
    Error_Handler();
  }

  /** Initializes the CPU, AHB and APB buses clocks
  */
  RCC_ClkInitStruct.ClockType = RCC_CLOCKTYPE_HCLK|RCC_CLOCKTYPE_SYSCLK
                              |RCC_CLOCKTYPE_PCLK1|RCC_CLOCKTYPE_PCLK2;
  RCC_ClkInitStruct.SYSCLKSource = RCC_SYSCLKSOURCE_PLLCLK;
  RCC_ClkInitStruct.AHBCLKDivider = RCC_SYSCLK_DIV1;
  RCC_ClkInitStruct.APB1CLKDivider = RCC_HCLK_DIV1;
  RCC_ClkInitStruct.APB2CLKDivider = RCC_HCLK_DIV1;

  if (HAL_RCC_ClockConfig(&RCC_ClkInitStruct, FLASH_LATENCY_4) != HAL_OK)
  {
    Error_Handler();
  }
}

void PeriphCommonClock_Config(void)
{
  RCC_PeriphCLKInitTypeDef PeriphClkInit = {0};

  /** Initializes the peripherals clock
  */
  PeriphClkInit.PeriphClockSelection = RCC_PERIPHCLK_ADC;
  PeriphClkInit.AdcClockSelection = RCC_ADCCLKSOURCE_PLLSAI1;
  PeriphClkInit.PLLSAI1.PLLSAI1Source = RCC_PLLSOURCE_HSI;
  PeriphClkInit.PLLSAI1.PLLSAI1M = 1;
  PeriphClkInit.PLLSAI1.PLLSAI1N = 8;
  PeriphClkInit.PLLSAI1.PLLSAI1P = RCC_PLLP_DIV7;
  PeriphClkInit.PLLSAI1.PLLSAI1Q = RCC_PLLQ_DIV2;
  PeriphClkInit.PLLSAI1.PLLSAI1R = RCC_PLLR_DIV2;
  PeriphClkInit.PLLSAI1.PLLSAI1ClockOut = RCC_PLLSAI1_ADC1CLK;
  if (HAL_RCCEx_PeriphCLKConfig(&PeriphClkInit) != HAL_OK)
  {
    Error_Handler();
  }
}

static void MX_ADC1_Init(void)
{

  ADC_MultiModeTypeDef multimode = {0};
  ADC_ChannelConfTypeDef sConfig = {0};

  /** Common config
  */
  hadc1.Instance = ADC1;
  hadc1.Init.ClockPrescaler = ADC_CLOCK_ASYNC_DIV1;
  hadc1.Init.Resolution = ADC_RESOLUTION_12B;
  hadc1.Init.DataAlign = ADC_DATAALIGN_RIGHT;
  hadc1.Init.ScanConvMode = ADC_SCAN_DISABLE;
  hadc1.Init.EOCSelection = ADC_EOC_SINGLE_CONV;
  hadc1.Init.LowPowerAutoWait = DISABLE;
  hadc1.Init.ContinuousConvMode = DISABLE;
  hadc1.Init.NbrOfConversion = 1;
  hadc1.Init.DiscontinuousConvMode = DISABLE;
  hadc1.Init.ExternalTrigConv = ADC_SOFTWARE_START;
  hadc1.Init.ExternalTrigConvEdge = ADC_EXTERNALTRIGCONVEDGE_NONE;
  hadc1.Init.DMAContinuousRequests = DISABLE;
  hadc1.Init.Overrun = ADC_OVR_DATA_PRESERVED;
  hadc1.Init.OversamplingMode = DISABLE;
  if (HAL_ADC_Init(&hadc1) != HAL_OK)
  {
    Error_Handler();
  }

  /** Configure the ADC multi-mode
  */
  multimode.Mode = ADC_MODE_INDEPENDENT;
  if (HAL_ADCEx_MultiModeConfigChannel(&hadc1, &multimode) != HAL_OK)
  {
    Error_Handler();
  }

  /** Configure Regular Channel
  */
  sConfig.Channel = ADC_CHANNEL_5;
  sConfig.Rank = ADC_REGULAR_RANK_1;
  sConfig.SamplingTime = ADC_SAMPLETIME_2CYCLES_5;
  sConfig.SingleDiff = ADC_SINGLE_ENDED;
  sConfig.OffsetNumber = ADC_OFFSET_NONE;
  sConfig.Offset = 0;
  if (HAL_ADC_ConfigChannel(&hadc1, &sConfig) != HAL_OK)
  {
    Error_Handler();
  }

}

static void MX_ADC2_Init(void)
{

  ADC_ChannelConfTypeDef sConfig = {0};

  /** Common config
  */
  hadc2.Instance = ADC2;
  hadc2.Init.ClockPrescaler = ADC_CLOCK_ASYNC_DIV1;
  hadc2.Init.Resolution = ADC_RESOLUTION_12B;
  hadc2.Init.DataAlign = ADC_DATAALIGN_RIGHT;
  hadc2.Init.ScanConvMode = ADC_SCAN_DISABLE;
  hadc2.Init.EOCSelection = ADC_EOC_SINGLE_CONV;
  hadc2.Init.LowPowerAutoWait = DISABLE;
  hadc2.Init.ContinuousConvMode = DISABLE;
  hadc2.Init.NbrOfConversion = 1;
  hadc2.Init.DiscontinuousConvMode = DISABLE;
  hadc2.Init.ExternalTrigConv = ADC_SOFTWARE_START;
  hadc2.Init.ExternalTrigConvEdge = ADC_EXTERNALTRIGCONVEDGE_NONE;
  hadc2.Init.DMAContinuousRequests = DISABLE;
  hadc2.Init.Overrun = ADC_OVR_DATA_PRESERVED;
  hadc2.Init.OversamplingMode = DISABLE;
  if (HAL_ADC_Init(&hadc2) != HAL_OK)
  {
    Error_Handler();
  }

  /** Configure Regular Channel
  */
  sConfig.Channel = ADC_CHANNEL_6;
  sConfig.Rank = ADC_REGULAR_RANK_1;
  sConfig.SamplingTime = ADC_SAMPLETIME_2CYCLES_5;
  sConfig.SingleDiff = ADC_SINGLE_ENDED;
  sConfig.OffsetNumber = ADC_OFFSET_NONE;
  sConfig.Offset = 0;
  if (HAL_ADC_ConfigChannel(&hadc2, &sConfig) != HAL_OK)
  {
    Error_Handler();
  }

}

static void MX_I2C1_Init(void)
{

  hi2c1.Instance = I2C1;
  hi2c1.Init.Timing = 0x10D19CE4;
  hi2c1.Init.OwnAddress1 = 0;
  hi2c1.Init.AddressingMode = I2C_ADDRESSINGMODE_7BIT;
  hi2c1.Init.DualAddressMode = I2C_DUALADDRESS_DISABLE;
  hi2c1.Init.OwnAddress2 = 0;
  hi2c1.Init.OwnAddress2Masks = I2C_OA2_NOMASK;
  hi2c1.Init.GeneralCallMode = I2C_GENERALCALL_DISABLE;
  hi2c1.Init.NoStretchMode = I2C_NOSTRETCH_DISABLE;
  if (HAL_I2C_Init(&hi2c1) != HAL_OK)
  {
    Error_Handler();
  }

  /** Configure Analogue filter
  */
  if (HAL_I2CEx_ConfigAnalogFilter(&hi2c1, I2C_ANALOGFILTER_ENABLE) != HAL_OK)
  {
    Error_Handler();
  }

  /** Configure Digital filter
  */
  if (HAL_I2CEx_ConfigDigitalFilter(&hi2c1, 0) != HAL_OK)
  {
    Error_Handler();
  }

}

static void MX_SPI1_Init(void)
{

  /* SPI1 parameter configuration*/
  hspi1.Instance = SPI1;
  hspi1.Init.Mode = SPI_MODE_MASTER;
  hspi1.Init.Direction = SPI_DIRECTION_2LINES;
  hspi1.Init.DataSize = SPI_DATASIZE_8BIT;
  hspi1.Init.CLKPolarity = SPI_POLARITY_LOW;
  hspi1.Init.CLKPhase = SPI_PHASE_1EDGE;
  hspi1.Init.NSS = SPI_NSS_SOFT;
  hspi1.Init.BaudRatePrescaler = SPI_BAUDRATEPRESCALER_4;
  hspi1.Init.FirstBit = SPI_FIRSTBIT_MSB;
  hspi1.Init.TIMode = SPI_TIMODE_DISABLE;
  hspi1.Init.CRCCalculation = SPI_CRCCALCULATION_DISABLE;
  hspi1.Init.CRCPolynomial = 7;
  hspi1.Init.CRCLength = SPI_CRC_LENGTH_DATASIZE;
  hspi1.Init.NSSPMode = SPI_NSS_PULSE_ENABLE;
  if (HAL_SPI_Init(&hspi1) != HAL_OK)
  {
    Error_Handler();
  }

}

static void MX_TIM16_Init(void)
{

  htim16.Instance = TIM16;
  htim16.Init.Prescaler = 7999;
  htim16.Init.CounterMode = TIM_COUNTERMODE_UP;
  htim16.Init.Period = 999;
  htim16.Init.ClockDivision = TIM_CLOCKDIVISION_DIV1;
  htim16.Init.RepetitionCounter = 0;
  htim16.Init.AutoReloadPreload = TIM_AUTORELOAD_PRELOAD_DISABLE;
  if (HAL_TIM_Base_Init(&htim16) != HAL_OK)
  {
    Error_Handler();
  }

}

static void MX_GPIO_Init(void)
{
  GPIO_InitTypeDef GPIO_InitStruct = {0};

  /* GPIO Ports Clock Enable */
  __HAL_RCC_GPIOC_CLK_ENABLE();
  __HAL_RCC_GPIOH_CLK_ENABLE();
  __HAL_RCC_GPIOA_CLK_ENABLE();
  __HAL_RCC_GPIOB_CLK_ENABLE();

  /*Configure GPIO pin Output Level */
  HAL_GPIO_WritePin(GPIOC, RST_Pin|DC_Pin, GPIO_PIN_RESET);

  /*Configure GPIO pin Output Level */
  HAL_GPIO_WritePin(CS_GPIO_Port, CS_Pin, GPIO_PIN_RESET);

  /*Configure GPIO pins : RST_Pin DC_Pin */
  GPIO_InitStruct.Pin = RST_Pin|DC_Pin;
  GPIO_InitStruct.Mode = GPIO_MODE_OUTPUT_PP;
  GPIO_InitStruct.Pull = GPIO_NOPULL;
  GPIO_InitStruct.Speed = GPIO_SPEED_FREQ_LOW;
  HAL_GPIO_Init(GPIOC, &GPIO_InitStruct);

  /*Configure GPIO pin : SW_Pin */
  GPIO_InitStruct.Pin = SW_Pin;
  GPIO_InitStruct.Mode = GPIO_MODE_IT_RISING;
  GPIO_InitStruct.Pull = GPIO_PULLUP;
  HAL_GPIO_Init(SW_GPIO_Port, &GPIO_InitStruct);

  /*Configure GPIO pin : CS_Pin */
  GPIO_InitStruct.Pin = CS_Pin;
  GPIO_InitStruct.Mode = GPIO_MODE_OUTPUT_PP;
  GPIO_InitStruct.Pull = GPIO_NOPULL;
  GPIO_InitStruct.Speed = GPIO_SPEED_FREQ_LOW;
  HAL_GPIO_Init(CS_GPIO_Port, &GPIO_InitStruct);

  /* EXTI interrupt init*/
  HAL_NVIC_SetPriority(EXTI4_IRQn, 3, 0);
  HAL_NVIC_EnableIRQ(EXTI4_IRQn);

}

/* USER CODE BEGIN 4 */
//Timer
void HAL_TIM_PeriodElapsedCallback(TIM_HandleTypeDef *htim)
{
	// Check which timer triggered this callback
	if (htim == &htim16) // if the triggered timer was Timer 16
	{
		int ADC_RANGE = 4096;
		// Start ADC Conversions
		HAL_ADC_Start(&hadc1);
		HAL_ADC_Start(&hadc2);
		// Wait for ADC conversions to complete
		HAL_ADC_PollForConversion(&hadc1, HAL_MAX_DELAY);
		HAL_ADC_PollForConversion(&hadc2, HAL_MAX_DELAY);
		// Read ADC values
		uint16_t xjoyStepNumber = HAL_ADC_GetValue(&hadc1);
		uint16_t yjoyStepNumber = HAL_ADC_GetValue(&hadc2);
		// Convert ADC levels to a fraction of total
		float xjoyPercentage = ((float) xjoyStepNumber) / ADC_RANGE;
		float yjoyPercentage = ((float) yjoyStepNumber) / ADC_RANGE;

		// erase the cursor
		for (uint8_t y = cursor_y-1; y < cursor_y+2; y++) { // iterate over each row
		  for (uint8_t x = cursor_x-1; x < cursor_x+2; x++) { // iterate over each row
			  if(background[y][x] == 1) ST7735_DrawPixel(x, y, WHITE);
			  else ST7735_DrawPixel(x, y, BLACK);
		  }
		}
		// update the cursor position
		if (xjoyPercentage > .5) cursor_x += 5;
		else if (xjoyPercentage < .3) cursor_x -=5;
		if (cursor_x < 2 || cursor_x > 140) cursor_x = 1;
		else if (cursor_x > 126) cursor_x = 126;
		if (yjoyPercentage > .5) cursor_y += 5;
		else if (yjoyPercentage < .3) cursor_y -=5;
		if (cursor_y < 2 || cursor_y > 180) cursor_y = 1;
		else if (cursor_y > 158) cursor_y = 158;
		// draw the cursor
		for (uint8_t y = cursor_y-1; y < cursor_y+2; y++) { // iterate over each row
		  for (uint8_t x = cursor_x-1; x < cursor_x+2; x++) { // iterate over each row
			  ST7735_DrawPixel(x, y, BLUE);
		  }
		}
		time++;
	}
}
// interrupt
void HAL_GPIO_EXTI_Callback(uint16_t GPIO_Pin) {
	// check if the switch triggered the interrupt
	if (GPIO_Pin == SW_Pin && time > 2) {
		// Type a number on the Character LCD depending on where the cursor is located
		if (cursor_x < 42){
			if (cursor_y < 52) CharLCD_Write_String("7");
			else if (cursor_y < 106) CharLCD_Write_String("4");
			else CharLCD_Write_String("1");
		} else if (cursor_x < 84){
			if (cursor_y < 52) CharLCD_Write_String("8");
			else if (cursor_y < 106) CharLCD_Write_String("5");
			else CharLCD_Write_String("2");
		} else {
			if (cursor_y < 52) CharLCD_Write_String("9");
			else if (cursor_y < 106) CharLCD_Write_String("6");
			else CharLCD_Write_String("3");
		}
		time = 0; // reset the debounce timer
	}
}
/**
 * @brief Write a 4-bit nibble to the LCD via I2C
 * @param nibble: 4-bit data to send (lower 4 bits)
 * @param dc: data/command (1 = data, 0 = command)
 * @retval None
 */
void CharLCD_Write_Nibble(uint8_t nibble, uint8_t dc) {
 uint8_t data = nibble << D4_BIT; // Shift nibble to D4-D7 position
 data |= dc << DC_BIT; // Set DC bit for data/command selection
 data |= 1 << BL_BIT; // Include backlight state in data
 data |= 1 << EN_BIT; // Set enable bit high
 HAL_I2C_Master_Transmit(&hi2c1, I2C_ADDR << 1, &data, 1, 100); // Send data with EN high
 HAL_Delay(1); // Wait for data setup
 data &= ~(1 << EN_BIT); // Clear enable bit (falling edge triggers LCD)
 HAL_I2C_Master_Transmit(&hi2c1, I2C_ADDR << 1, &data, 1, 100); // Send data with EN low
}
/**
 * @brief Send command to LCD
 * @param cmd: 8-bit command to send to LCD controller
 * @retval None
 */
void CharLCD_Send_Cmd(uint8_t cmd) {
 uint8_t upper_nibble = cmd >> 4; // Extract upper 4 bits
 uint8_t lower_nibble = cmd & 0x0F; // Extract lower 4 bits
 CharLCD_Write_Nibble(upper_nibble, 0); // Send upper nibble (DC=0 for command)
 CharLCD_Write_Nibble(lower_nibble, 0); // Send lower nibble (DC=0 for command)
 if (cmd == 0x01 || cmd == 0x02) { // Clear display or return home commands
 HAL_Delay(2); // These commands need extra time
 }
}
/**
 * @brief Send data (character) to LCD
 * @param data: 8-bit character data to display
 * @retval None
 */
void CharLCD_Send_Data(uint8_t data) {
 uint8_t upper_nibble = data >> 4; // Extract upper 4 bits
 uint8_t lower_nibble = data & 0x0F; // Extract lower 4 bits
 CharLCD_Write_Nibble(upper_nibble, 1); // Send upper nibble (DC=1 for data)
 CharLCD_Write_Nibble(lower_nibble, 1); // Send lower nibble (DC=1 for data)
}
/**
 * @brief Initialize LCD in 4-bit mode via I2C
 * @param None
 * @retval None
 */
void CharLCD_Init() {
 HAL_Delay(50); // Wait for LCD power-on reset (>40ms)
 CharLCD_Write_Nibble(0x03, 0); // Function set: 8-bit mode (first attempt)
 HAL_Delay(5); // Wait >4.1ms
 CharLCD_Write_Nibble(0x03, 0); // Function set: 8-bit mode (second attempt)
 HAL_Delay(1); // Wait >100us
 CharLCD_Write_Nibble(0x03, 0); // Function set: 8-bit mode (third attempt)
 HAL_Delay(1); // Wait >100us
 CharLCD_Write_Nibble(0x02, 0); // Function set: switch to 4-bit mode
 CharLCD_Send_Cmd(0x28); // Function set: 4-bit, 2 lines, 5x8 font
 CharLCD_Send_Cmd(0x0C); // Display control: display on/cursor off/blink off
 CharLCD_Send_Cmd(0x06); // Entry mode: increment cursor, no shift
 CharLCD_Send_Cmd(0x01); // Clear display
 HAL_Delay(2); // Wait for clear display command
}
/**
 * @brief Write string to LCD at current cursor position
 * @param str: Pointer to null-terminated string
 * @retval None
 */
void CharLCD_Write_String(char *str) {
 while (*str) { // Loop until null terminator
 CharLCD_Send_Data(*str++); // Send each character and increment pointer
 }
}
/**
 * @brief Set cursor position on LCD
 * @param row: Row number (0 or 1 for 2-line display)
 * @param column: Column number (0 to display width - 1)
 * @retval None
 */
void CharLCD_Set_Cursor(uint8_t row, uint8_t column) {
 uint8_t address;
 switch (row) {
 case 0:
 address = 0x00; break; // First line starts at address 0x00
 case 1:
 address = 0x40; break; // Second line starts at address 0x40
 default:
 address = 0x00; // Default to first line for invalid row
 }
 address += column; // Add column offset
 CharLCD_Send_Cmd(0x80 | address); // Set DDRAM address command (0x80 + address)
}
/**
 * @brief Clear LCD display and return cursor to home position
 * @param None
 * @retval None
 */
void CharLCD_Clear(void) {
 CharLCD_Send_Cmd(0x01); // Clear display command
 HAL_Delay(2); // Wait for command execution
}
/**
 * @brief Transmits the provided bytes as data to the ST7735 over SPI1
 * @param data: the array of data / pointer to where the data starts
 * @param size: the number of bytes of data to transit
 * @retval None
 */
void ST7735_WriteData(uint8_t data[], uint16_t size) {
 // Change the DC (Data/Command) pin to "Data" mode
 HAL_GPIO_WritePin(DC_GPIO_Port, DC_Pin, 1);
 // Send the data
 HAL_GPIO_WritePin(CS_GPIO_Port, CS_Pin, 0); // select the device
 HAL_SPI_Transmit(&hspi1, data, size, HAL_MAX_DELAY); // transmit bytes
 HAL_GPIO_WritePin(CS_GPIO_Port, CS_Pin, 1); // deselect the device
}
/**
 * @brief Transmits the provided byte as a command to the ST7735 over SPI1
 * @param cmd: the 1-byte command to transmit
 * @retval None
 */
void ST7735_WriteCommand(uint8_t cmd) {
 // Change DC (Data/Command) pin to "Command" mode
 HAL_GPIO_WritePin(DC_GPIO_Port, DC_Pin, 0);
 // Send the command
 HAL_GPIO_WritePin(CS_GPIO_Port, CS_Pin, 0); // select the device
 HAL_SPI_Transmit (&hspi1, &cmd, 1, HAL_MAX_DELAY); // transmit byte
 HAL_GPIO_WritePin(CS_GPIO_Port, CS_Pin, 1); // deselect the device
}
/**
 * @brief Initializes the ST7735 over SPI1 with startup commands
 * @param None
 * @retval None
 */
void ST7735_Init(void) {
 // Perform a hardware reset (reset low pulse)
 HAL_GPIO_WritePin(RST_GPIO_Port, RST_Pin, GPIO_PIN_RESET); // RST pin low
 HAL_Delay(5); // wait 5ms
 HAL_GPIO_WritePin(RST_GPIO_Port, RST_Pin, GPIO_PIN_SET); // RST pin high
 HAL_Delay(5); // wait 5ms
// Perform a software reset
 ST7735_WriteCommand(SWRESET); // send a SWRESET (Software reset) command
 HAL_Delay(150);
 // Wake the display (exit low-power sleep mode)
 ST7735_WriteCommand(SLPOUT); // Send a SLPOUT (Sleep out) command
 HAL_Delay(150);
 // Enter "Interface Pixel Format" mode and set to 16-bit color
 ST7735_WriteCommand(COLMOD); // Send a COLMOD (Color Mode) command
 uint8_t colorMode = 0x05; // color mode = 16-bit/pixel
 ST7735_WriteData(&colorMode, 1); // send color mode value as a data message
 // Enter "Memory Data Access Control" mode and set to row/column order
 ST7735_WriteCommand(MADCTL); // Send a MADCTL (Memory Access Data Control) command
 uint8_t accessMode = 0xC8; // access mode = row/column order
 ST7735_WriteData(&accessMode, 1); // send access mode value as a data message
 // Turn on display
 ST7735_WriteCommand(DISPON); // send a DISPON (Display On) command
 HAL_Delay(10);
}
/**
 * @brief Specifies the address window where the next pixel data will go
 * @param xStart: the starting x address
 * @param yStart: the starting y address
 * @param xEnd: the ending x address
 * @param yEnd: the ending y address
 * @retval None
 */
void ST7735_SetAddressWindow(uint16_t xStart, uint16_t yStart, uint16_t xEnd, uint16_t yEnd) {
 // Early exit if any dimensions are out of bounds
 if ((xStart > xEnd) || (yStart > yEnd) || (xEnd >= NUMCOLS) || (yEnd >= NUMROWS)) return;
 // Data array for configuration data
 uint8_t address[4];
 // Set column start/end
 ST7735_WriteCommand(0x2A); // Enter "Column address set" mode
 address[0] = xStart >> 8; // upper 8 bits of x starting address
 address[1] = xStart & 0xFF; // lower 8 bits of x starting address
 address[2] = xEnd >> 8; // upper 8 bits of x ending address
 address[3] = xEnd & 0xFF; // lower 8 bits of x ending address
 ST7735_WriteData(address, 4); // Transmit the 4 bytes of parameter data
 // Set row start/end
 ST7735_WriteCommand(0x2B); // Enter "Row address set" mode
 address[0] = yStart >> 8; // upper 8 bits of y starting address
 address[1] = yStart & 0xFF; // lower 8 bits of y starting address
 address[2] = yEnd >> 8; // upper 8 bits of y ending address
 address[3] = yEnd & 0xFF; // lower 8 bits of y ending address
 ST7735_WriteData(address, 4); // Transmit the 4 bytes of parameter data
 // Get ready to send pixel data
 ST7735_WriteCommand(0x2C); // Enter "RAM Write" mode (pixel writing mode)
}
/**
 * @brief Updates a specified pixel to a specified color
 * @param x: the x address of the pixel
 * @param y: the y address of the pixel
 * @param color: two-byte color value (bbbbb gggggg rrrrr)
 * @retval None
 */
void ST7735_DrawPixel(uint8_t x, uint8_t y, uint16_t color) {
 // Early exit if (x,y) is out of bounds
 if ((x >= NUMCOLS) || (y >= NUMROWS)) return;
 // Single pixel, so start and stop on the same (x,y) pixel
 ST7735_SetAddressWindow(x, y, x, y);
 // Organize the color as a two-byte value
 uint8_t pixelData[2] = { color >> 8, color & 0xFF }; // swap for Big Endian
 // Send the data
 ST7735_WriteData(pixelData, 2);
}
/**
 * @brief draws the graphics on the screen
 * @param None
 * @retval None
 */
void ST7735_StartScreen() {
	for (uint8_t y = 0; y < 160; y++) { // iterate over each row
		for (uint8_t x = 0; x < 128; x++) { // iterate over each row
			// draw on the screen with whatever is in the background array
			if(background[y][x] == 1) ST7735_DrawPixel(x, y, WHITE);
			else ST7735_DrawPixel(x, y, BLACK);
		}
	}
}
/* USER CODE END 4 */

void Error_Handler(void)
{
  __disable_irq();
  while (1)
  {
  }
}
